[part 1 of 2: packages /AUTOSAR/V2xM/ClientServerInterfaces_Blueprint to /AUTOSAR/Csm/ClientServerInterfaces_Blueprint]
AUTOSAR XML (schema 00046)
package /AUTOSAR/V2xM/ClientServerInterfaces_Blueprint
  4 x client server interface, all with is-service=true:
    V2xM_GeoMath  # Interfaces for Applications to math functions
      operation Distance: possible-error=[V2xM_GeoMath/E_OK, V2xM_GeoMath/E_NOT_OK]  # Service for Calculating the distance between two geographical points
        5 x arg:
          latitudeA: type=sint32, direction=IN  # Latitude of geographical point A
          longitudeA: type=sint32, direction=IN  # Longitude of geographical point A
          latitudeB: type=sint32, direction=IN  # Latitude of geographical point B
          longitudeB: type=sint32, direction=IN  # Longitude of geographical point B
          distance: type=float32, direction=OUT  # Distance between geographical points A and B in [m].
      operation HeadingInTolerance: possible-error=[V2xM_GeoMath/E_OK, V2xM_GeoMath/E_NOT_OK]  # Service for Calculating if difference of heading values are within a tolerance value
        4 x arg:
          heading1: type=float32, direction=IN  # First heading value
          heading2: type=float32, direction=IN  # Next heading value
          toleranceValue: type=float32, direction=IN  # Tolerated difference between heading1 and heading2
          tolerated: type=boolean, direction=OUT  # Return value
      error E_OK: error-code=0  # Operation successful
      error E_NOT_OK: error-code=1  # Operation failed
    V2xM_PseudonymChange  # Interfaces for Applications to lock and unlock pseudonym changes within the V2X-BSW-Stack.
      operation Lock: possible-error=[V2xM_PseudonymChange/E_OK, V2xM_PseudonymChange/E_NOT_OK]  # Service for locking the pseudonym change. See [SWS_V2xM_00078] for more information about locking the pseudonym change.
        arg Duration: type=uint16, direction=IN  # Duration to lock.
        arg HandleId: type=uint64, direction=OUT  # HandleId for manual Unlock
      operation Unlock: possible-error=[V2xM_PseudonymChange/E_OK, V2xM_PseudonymChange/E_NOT_OK]  # Service for unlocking the pseudonym change. See [SWS_V2xM_00079] for more information about locking the pseudonym change.
        arg HandleId: type=uint64, direction=IN  # HandleId to unlock
      error E_OK: error-code=0  # Operation successful
      error E_NOT_OK: error-code=1  # Operation failed
    V2xM_Sec  # Security related interfaces for applications
      operation Verify: possible-error=[V2xM_Sec/E_OK, V2xM_Sec/E_NOT_OK]  # Interfaces for Applications to verify messages on demand instead of verify all incoming messages, to reduce ECU load.
        arg TransactionId32: type=uint32, direction=IN  # TransactionId of the packet to be verified
        arg SecReport: type=V2xM_SecReportType, direction=OUT
      error E_OK: error-code=0  # Operation successful
      error E_NOT_OK: error-code=1  # Operation failed
    V2xM_Vdp  # Interfaces for Vehicle Data Provider (VDP) to get and set V2X related vehicle information in the BSW V2X-Stack
      4 x operation, all with possible-error=[V2xM_Vdp/E_OK, V2xM_Vdp/E_NOT_OK]:
        GetNextLongTermCertificateExpirationDate  # Service to get the certificate expiration date of the long term certificates that expires in the nearest future.
          arg ExpirationDate: type=uint32, direction=OUT  # Date is based on format Time32 that is specified in [19].
        GetNextPseudonymCertificateExpirationDate  # Service to get the certificate expiration date of the pseudonym certificates that expires in the nearest future.
          arg ExpirationDate: type=uint32, direction=OUT  # Date is based on format Time32 that is specified in [19].
        GetTime32  # Service to get the current reference time.
          arg Time32: type=uint32, direction=OUT  # Time is based on TAI mod 2^32, where TAI is the number of elapsed TAI milliseconds since 2004-01-01 00:00:00.000.
        SetPositionAndTime  # Service for setting positional and time information relevant for the V2X-Stack
          arg positionAndTime: type=V2xM_PositionAndTimeType, direction=IN
      error E_OK: error-code=0  # Operation successful
      error E_NOT_OK: error-code=1  # Operation failed
package /AUTOSAR/V2xM/ServiceSwComponentTypes_Blueprint
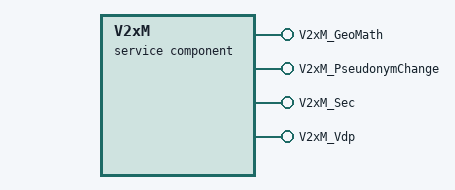
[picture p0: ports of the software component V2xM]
  service sw component type V2xM
    4 x provide port:
      V2xM_GeoMath: provided-interface=V2xM_GeoMath  # Service port for geographical calculation requests.
      V2xM_PseudonymChange: provided-interface=V2xM_PseudonymChange  # Service port for pseudonym lock and unlock requests.
      V2xM_Sec: provided-interface=V2xM_Sec  # Service port for security operations of V2X messages.
      V2xM_Vdp: provided-interface=V2xM_Vdp  # Service port for exchange of vehicle related data. This port is used by the Vehicle Data Provider SW-C.
    behavior V2xMInternalBehavior
package /AUTOSAR/V2xFac/ClientServerInterfaces_Blueprint
  client server interface V2xFacDenBs: is-service=true  # Service of V2xFac module basic service DEN
    operation TerminateEvent: possible-error=[V2xFacDenBs/E_OK, V2xFacDenBs/E_NOT_OK, E_ACTION_ID_NONEXISTENT, E_DENM_UNCONSTRUCTABLE, E_DENM_TIME_OUT]  # Requests termination of an existing DENM ( see [11] chapter 4 and 5.4.1.4 )
      6 x arg:
        EventData: type=V2xFac_DenMsgType, direction=IN  # Pre-filled DENM message structure, including the ActionID from TriggerEvent
        RepetitionDuration: type=uint32, direction=IN  # Duration of the DENM repetition in units of milliseconds
        RepetitionInterval: type=uint16, direction=IN  # Interval of DENM repetition in units of milliseconds
        DestinationArea: type=V2xFac_GnDestinationAreaType, direction=IN  # Destination area for DENM dissemination as specified in ETSI EN 302 931.
        TrafficClass: type=V2xFac_TrafficClassIdType, direction=IN  # GN traffic class of the DENM as defined in ETSI EN 302 636-4-1
        ActionID: type=V2xFac_ActionIdType, direction=OUT  # The DEN basic service returns the actionID or other applicable identifier created by the DEN basic service to the requesting ITS-S application
    operation TriggerEvent: possible-error=[V2xFacDenBs/E_OK, V2xFacDenBs/E_NOT_OK, E_DENM_UNCONSTRUCTABLE, E_DENM_TIME_OUT]  # Requests creation of a new DENM ( see [11] chapter 4 and 5.4.1.2 )
      6 x arg:
        EventData: type=V2xFac_DenMsgType, direction=IN  # Pre-filled DENM message structure
        RepetitionDuration: type=uint32, direction=IN  # Duration of the DENM repetition in units of milliseconds
        RepetitionInterval: type=uint16, direction=IN  # Interval of DENM repetition in units of milliseconds
        DestinationArea: type=V2xFac_GnDestinationAreaType, direction=IN  # Destination area for DENM dissemination as specified in ETSI EN 302 931.
        TrafficClass: type=V2xFac_TrafficClassIdType, direction=IN  # GN traffic class of the DENM as defined in ETSI EN 302 636-4-1
        ActionID: type=V2xFac_ActionIdType, direction=OUT  # The DEN basic service returns the actionID or other applicable identifier created by the DEN basic service to the requesting ITS-S application
    operation UpdateEvent: possible-error=[V2xFacDenBs/E_OK, V2xFacDenBs/E_NOT_OK, E_ACTION_ID_NONEXISTENT, E_DENM_UNCONSTRUCTABLE, E_DENM_TIME_OUT]  # Requests update of an existing DENM ( see [11] chapter 4 and 5.4.1.3 )
      6 x arg:
        EventData: type=V2xFac_DenMsgType, direction=IN  # Pre-filled DENM message structure, including the ActionID from TriggerEvent
        RepetitionDuration: type=uint32, direction=IN  # Duration of the DENM repetition in units of milliseconds
        RepetitionInterval: type=uint16, direction=IN  # Interval of DENM repetition in units of milliseconds
        DestinationArea: type=V2xFac_GnDestinationAreaType, direction=IN  # Destination area for DENM dissemination as specified in ETSI EN 302 931.
        TrafficClass: type=V2xFac_TrafficClassIdType, direction=IN  # GN traffic class of the DENM as defined in ETSI EN 302 636-4-1
        ActionID: type=V2xFac_ActionIdType, direction=OUT  # The DEN basic service returns the actionID or other applicable identifier created by the DEN basic service to the requesting ITS-S application
    5 x error:
      E_OK: error-code=0  # Operation successful
      E_NOT_OK: error-code=1  # Operation failed
      E_ACTION_ID_NONEXISTENT: error-code=2  # ActionID provided for Update/Termination does not exist
      E_DENM_UNCONSTRUCTABLE: error-code=3  # DENM couldn't be constructed
      E_DENM_TIME_OUT: error-code=4  # DENM hasn't been sent before timeout of DENM has been reached
package /AUTOSAR/V2xFac/SenderReceiverInterfaces_Blueprint
  6 x sender receiver interface:
    V2xApplRxIndicationCam: is-service=true  # Deliver received CAMs Applications
      data CamData: implementation-data-type=V2xFac_CamMessageRootType
    V2xApplRxIndicationDenm: is-service=true  # Deliver received DENMs to Applications
      data DenmData: implementation-data-type=V2xFac_DenmMessageRootType
    V2xApplRxIndicationIvim: is-service=true  # Deliver received IVIMs to Applications
      data IvimData: implementation-data-type=V2xFac_IvimDataType
    V2xApplRxIndicationMapem: is-service=true  # Deliver received MAPEMs to Applications
      data MapemData: implementation-data-type=V2xFac_MapemDataType
    V2xApplRxIndicationSpatem: is-service=true  # Deliver received SPATEMs to Applications
      data SpatemData: implementation-data-type=V2xFac_SpatemDataType
    V2xFacVdp  # Interface to receive data from VDP application
      data vdpData: implementation-data-type=V2xFac_CoopAwarenessType
package /AUTOSAR/V2xFac/ServiceSwComponentTypes_Blueprint
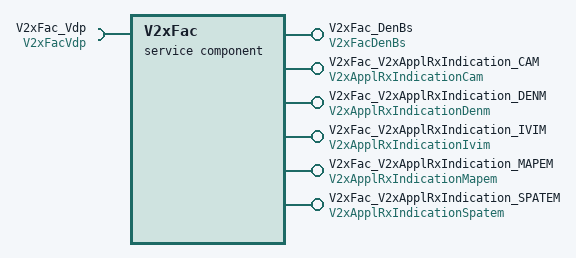
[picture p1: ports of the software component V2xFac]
  service sw component type V2xFac
    6 x provide port:
      V2xFac_DenBs: provided-interface=V2xFacDenBs  # Service port for DEN specific service requests
      V2xFac_V2xApplRxIndication_CAM: provided-interface=V2xApplRxIndicationCam  # Port for delivering received CAMs to application layer
      V2xFac_V2xApplRxIndication_DENM: provided-interface=V2xApplRxIndicationDenm  # Port for delivering received DENMs to application layer
      V2xFac_V2xApplRxIndication_IVIM: provided-interface=V2xApplRxIndicationIvim  # Port for delivering received IVIMs to application layer
      V2xFac_V2xApplRxIndication_MAPEM: provided-interface=V2xApplRxIndicationMapem  # Port for delivering received MAPEMs to application layer
      V2xFac_V2xApplRxIndication_SPATEM: provided-interface=V2xApplRxIndicationSpatem  # Port for delivering received SPATEMs to application layer
    require port V2xFac_Vdp: required-interface=V2xFacVdp  # Port for retrieving data from VDP application
    behavior V2xFacInternalBehavior
package /AUTOSAR/Dem/ClientServerInterfaces_Blueprint
  37 x client server interface, all with is-service=true:
    CallbackClearEventAllowed  # If configured, it gets the permission to clear a specific event from the SW-C. For each event, there can be one port of this interface type.
      operation ClearEventAllowed: possible-error=[CallbackClearEventAllowed/E_OK, CallbackClearEventAllowed/E_NOT_OK]
        arg Allowed: type=boolean, direction=OUT  # True - clearance of event is allowed False - clearance of event is not allowed
      error E_OK: error-code=0  # Operation successful
      error E_NOT_OK: error-code=1  # Operation failed
    CallbackEventDataChanged  # If configured it triggers SW-Cs on event related data changes. For each event, there can be one port of this interface type.
      operation EventDataChanged
    CallbackEventUdsStatusChanged  # If configured it triggers SW-Cs on event status byte changes. For each event, there can be several ports of this interface type.
      operation CallbackEventUdsStatusChanged
        arg EventStatusByteOld: type=Dem_UdsStatusByteType, direction=IN
        arg EventStatusByteNew: type=Dem_UdsStatusByteType, direction=IN
    CallbackGetFaultDetectCounter  # If configured it get the monitor-internal fault detection counter value of a specific event from the SW-C.
      operation GetFaultDetectionCounter: possible-error=[CallbackGetFaultDetectCounter/E_OK, CallbackGetFaultDetectCounter/E_NOT_OK]
        arg FaultDetectionCounter: type=sint8, direction=OUT  # Value of FaultDetectionCounter
      error E_OK: error-code=0  # Operation successful
      error E_NOT_OK: error-code=1  # Operation failed
    CallbackInitMonitorForEvent  # If configure it triggers an event-specific initialization of the monitor part of the SW-C). For each event, there can be one port of this interface type.
      operation InitMonitorForEvent: possible-error=[CallbackInitMonitorForEvent/E_OK, CallbackInitMonitorForEvent/E_NOT_OK]
        arg InitMonitorReason: type=Dem_InitMonitorReasonType, direction=IN
      error E_OK: error-code=0  # Operation successful
      error E_NOT_OK: error-code=1  # Operation failed
    CallbackMonitorStatusChange  # If configured it triggers SW-Cs on monitor status changes. For each event, there can be several ports of this interface type.
      operation MonitorStatusChanged
    CallbackComponentStatusChanged
      operation ComponentStatusChanged
        arg ComponentFailedStatus: type=boolean, direction=IN
    CallbackDTCStatusChange  # If configured it triggers SW-Cs on DTC status byte changes via DemCallbackDTCStatusChanged, DemCallbackOBDDTCStatusChanged, and / or DemCallbackJ1939DTCStatusChanged. There can be several ports of this interface type, provided globally by the Dem Service Component.
      operation DTCStatusChanged: possible-error=[CallbackDTCStatusChange/E_OK, CallbackDTCStatusChange/E_NOT_OK]
        arg DTC: type=uint32, direction=IN
        arg DTCStatusOld: type=Dem_UdsStatusByteType, direction=IN
        arg DTCStatusNew: type=Dem_UdsStatusByteType, direction=IN
      error E_OK: error-code=0  # Operation successful
      error E_NOT_OK: error-code=1  # Operation failed
    ClearDTC  # Provides the operations only related to complex device drivers. One port of this interface type is provided globally by the Dem Service Component. It has ClientId as a port-defined argument.
      operation ClearDTC: possible-error=[ClearDTC/E_OK, ClearDTC/E_NOT_OK, ClearDTC/DEM_PENDING, DEM_CLEAR_BUSY, DEM_CLEAR_MEMORY_ERROR, DEM_CLEAR_FAILED, ClearDTC/DEM_WRONG_DTC, ClearDTC/DEM_WRONG_DTCORIGIN, DEM_BUSY]
      operation SelectDTC: possible-error=[ClearDTC/E_OK, ClearDTC/E_NOT_OK]
        arg DTC: type=uint32, direction=IN
        arg DTCFormat: type=Dem_DTCFormatType, direction=IN
        arg DTCOrigin: type=Dem_DTCOriginType, direction=IN
      9 x error:
        E_OK: error-code=0  # Operation successful
        E_NOT_OK: error-code=1  # Operation failed
        DEM_PENDING: error-code=4  # Clearing the DTCs is currently in progress. The caller shall call this function again at a later moment.
        DEM_CLEAR_BUSY: error-code=5  # Another client is currently clearing DTCs. The requested operation will not be started and the caller shall try again at a later moment.
        DEM_CLEAR_MEMORY_ERROR: error-code=6  # An error occurred during erasing a memory location (e.g. if DemClearDTCBehavior is set to DEM_CLRRESP_NON-VOLATILE_FINISH and erasing of non-volatile-block failed).
        DEM_CLEAR_FAILED: error-code=7  # DTC clearing failed
        DEM_WRONG_DTC: error-code=8  # Selected DTC value in selected format does not exist or clearing is restricted by configuration to group of all DTCs only.
        DEM_WRONG_DTCORIGIN: error-code=9  # Selected DTCOrigin does not exist.
        DEM_BUSY: error-code=22  # A different Dem_SelectDTC dependent operation according to SWS_Dem_01253 of this client is currently in progress.
    ClearDtcNotification: variation-point={short-label=ClearDtcNotification, blueprint-condition=p=l-1=(count({ecuc(Dem/DemGeneral/DemEventMemorySet/DemClearDTCNotification/DemClearDtcNotificationFnc)} == NULL) > 0)}
      operation ClearDtcNotification: possible-error=ClearDtcNotification/E_OK
        arg DTC: type=uint32, direction=IN
        arg DTCFormat: type=Dem_DTCFormatType, direction=IN
        arg DTCOrigin: type=Dem_DTCOriginType, direction=IN
      error E_OK: error-code=0  # Operation successful
    DTCSuppression: variation-point={short-label=DTCSuppression, blueprint-condition=p=l-1=({ecuc(Dem/DemGeneral/DemSuppressionSupport)} == DEM_DTC_SUPPRESSION)}  # Provides the capability to control the suppression of DTCs. One port of this interface type is provided globally by the Dem Service Component.
      operation GetDTCSuppression: possible-error=[DTCSuppression/E_OK, DTCSuppression/E_NOT_OK, DTCSuppression/DEM_PENDING, DTCSuppression/DEM_WRONG_DTC, DTCSuppression/DEM_WRONG_DTCORIGIN]
        arg ClientID: type=uint8, direction=IN  # Unique client id, assigned to the instance of the calling module.
        arg SuppressionStatus: type=boolean, direction=OUT  # Defines whether the respective DTC is suppressed (TRUE) or enabled (FALSE).
      operation SetDTCSuppression: possible-error=[DTCSuppression/E_OK, DTCSuppression/E_NOT_OK, DTCSuppression/DEM_WRONG_DTC, DTCSuppression/DEM_WRONG_DTCORIGIN]
        arg ClientID: type=uint8, direction=IN  # Unique client id, assigned to the instance of the calling module.
        arg SuppressionStatus: type=boolean, direction=IN
      5 x error:
        E_OK: error-code=0  # Operation successful
        E_NOT_OK: error-code=1  # Operation failed
        DEM_PENDING: error-code=4  # Clearing the DTCs is currently in progress. The caller shall call this function again at a later moment.
        DEM_WRONG_DTC: error-code=8  # Selected DTC value in selected format does not exist or clearing is restricted by configuration to group of all DTCs only.
        DEM_WRONG_DTCORIGIN: error-code=9  # Selected DTCOrigin does not exist.
    EventAvailable: variation-point={short-label=EventAvailable, blueprint-condition=p=l-1={ecuc(Dem/DemGeneral/DemAvailabilitySupport)} == DEM_EVENT_AVAILABILITY}
      operation SetEventAvailable: possible-error=[EventAvailable/E_OK, EventAvailable/E_NOT_OK]
        arg AvailableStatus: type=boolean, direction=IN
      error E_OK: error-code=0  # Operation successful
      error E_NOT_OK: error-code=1  # Operation failed
    EventFailureCycleCounterThreshold: variation-point={short-label=EventFailureCycleCounterThreshold, blueprint-condition=p=l-1=(count({ecuc(Dem/DemConfigSet/DemEventParameter/DemEventFailureCycleCounterThresholdAdaptable)} == TRUE) > 0 )}  # Provides the capability for dynamical adaptation of the failure cycle threshold. One port of this interface is provided per diagnostic event with EventId as a port-defined argument.
      operation SetEventFailureCycleCounterThreshold: possible-error=[EventFailureCycleCounterThreshold/E_OK, EventFailureCycleCounterThreshold/E_NOT_OK]
        arg FailureCycleCounterThreshold: type=uint8, direction=IN  # Failure cycle counter threshold of event to be set.
      error E_OK: error-code=0  # Operation successful
      error E_NOT_OK: error-code=1  # Operation failed
    DataServices: variation-point={short-label=DataServicesCS, blueprint-condition=p=l-1=(({ecuc(Dem/DemGeneral/DemDataElementClass)} instanceof {ecuc(Dem/DemGeneral/DemDataElementClass/DemExternalCSDataElementClass)})&& ({ecuc(Dem/DemGeneral/DemDataElementClass/DemExternalCSDataElementClass/DemDataElementUsePort)} == true))}  # If configured it gets the data element value contained in a DID, a PID, or an extended data record from the respective SW-C via client/server or sender/receiver communication (refer to Figure "Dem and Dcm module requests PID data elements of SW-C via ReadData operation"). For each data element, one port of this interface type is provided by the SW-Cs.
      operation ReadData: possible-error=[DataServices/E_OK, DataServices/E_NOT_OK]  # The server is not allowed to return E_NOT_OK, but shall always provide a valid data value (e.g. a default/replacement value in an error-case) to Dcm/Dem nevertheless the signature of the operation includes E_NOT_OK to ensure compatibility between server runnable and RTE Call API, since the RTE may return negative Std_Return values in certain cases (e.g. partition of server stopped)
        arg Data: type=Dem_DataType, direction=OUT
        arg monitorData0: type=Dem_MonitorDataType, direction=IN, variation-point=blueprint-condition=p=l-1=({ecuc(Dem/DemGeneral/DemDataElementClass/DemExternalCSDataElementClass/DemDataElementProvideMonitorData)} == true))
      error E_OK: error-code=0  # Operation successful
      error E_NOT_OK: error-code=1  # Operation failed
    DiagnosticMonitor_MonitorData  # Provide means to report diagnostic monitor status with monitor data.
      operation SetEventStatusWithMonitorData: possible-error=[DiagnosticMonitor_MonitorData/E_OK, DiagnosticMonitor_MonitorData/E_NOT_OK]
        arg EventStatus: type=Dem_EventStatusType, direction=IN
        arg monitorData0: type=Dem_MonitorDataType, direction=IN
        arg monitorData1: type=Dem_MonitorDataType, direction=IN
      error E_OK: error-code=0  # Operation successful
      error E_NOT_OK: error-code=1  # Operation failed
    DTRCentralReport  # Available if OBD support is configured.
      operation SetDTR: possible-error=[DTRCentralReport/E_OK, DTRCentralReport/E_NOT_OK]
        4 x arg, all with direction=IN:
          TestResult: type=sint32
          LowerLimit: type=sint32
          UpperLimit: type=sint32
          Ctrlval: type=Dem_DTRControlType
      error E_OK: error-code=0  # Operation successful
      error E_NOT_OK: error-code=1  # Operation failed
    EnableCondition  # If at least one enable condition is configured it provide the capability to set an enable condition. One port of this interface type is provided per enable condition by the Dem Service Component. It has EnableConditionId as a port-defined argument.
      operation SetEnableCondition: possible-error=[EnableCondition/E_OK, EnableCondition/E_NOT_OK]
        arg ConditionFulfilled: type=boolean, direction=IN
      error E_OK: error-code=0  # Operation successful
      error E_NOT_OK: error-code=1  # Operation failed
    DiagnosticMonitor  # Provide the capability to modify the event information. One port of this interface type is provided per application-related diagnostic event by the Dem Service Component. It has EventId as a port-defined argument.
      6 x operation, all with possible-error=[DiagnosticMonitor/E_OK, DiagnosticMonitor/E_NOT_OK]:
        ClearPrestoredFreezeFrame: variation-point=blueprint-condition=p=l-1={ecuc(Dem/DemGeneral/DemMaxNumberPrestoredFF)} > 0
        PrestoreFreezeFrame: variation-point=blueprint-condition=p=l-1={ecuc(Dem/DemGeneral/DemMaxNumberPrestoredFF)} > 0
        ResetEventDebounceStatus: variation-point=blueprint-condition=p=l-1=({ecuc(Dem/DemGeneral/DemDebounceCounterBasedSupport)} == true) || ({ecuc(Dem/DemGeneral/DemDebounceTimeBasedSupport)} == true)
          arg DebounceResetStatus: type=Dem_DebounceResetStatusType, direction=IN
        ResetEventStatus
        SetEventDisabled: variation-point=blueprint-condition=p=l-1={ecuc(Dem/DemGeneral.DemOBDSupport)} != DEM_OBD_NO_OBD_SUPPORT
        SetEventStatus
          arg EventStatus: type=Dem_EventStatusType, direction=IN
      error E_OK: error-code=0  # Operation successful
      error E_NOT_OK: error-code=1  # Operation failed
    DiagnosticInfo  # Provides the capability to obtain the event information. One port of this interface type is provided per diagnostic event by the Dem Service Component. It has EventId as a port-defined argument.
      7 x operation:
        GetDTCOfEvent: possible-error=[DiagnosticInfo/E_OK, DiagnosticInfo/E_NOT_OK, DiagnosticInfo/DEM_E_NO_DTC_AVAILABLE]
          arg DTCFormat: type=Dem_DTCFormatType, direction=IN
          arg DTCOfEvent: type=uint32, direction=OUT
        GetDebouncingOfEvent: possible-error=[DiagnosticInfo/E_OK, DiagnosticInfo/E_NOT_OK], variation-point=blueprint-condition=p=l-1=(({ecuc(Dem/DemConfigSet/DemEventParameter/DemDebounceAlgorithmClass)} instanceof {ecuc(Dem/DemConfigSet/DemEventParameter/DemDebounceAlgorithmClass/DemDebounceCounterBased)}) ||({ecuc(Dem/DemConfigSet/DemEventParameter/DemDebounceAlgorithmClass)} instanceof {ecuc(Dem/DemConfigSet/DemEventParameter/DemDebounceAlgorithmClass/DemDebounceTimeBase)}))
          arg DebouncingState: type=Dem_DebouncingStateType, direction=OUT  # Bit 0 Temporarily Defective (corresponds to 0 < FDC < 127) Bit 1 finally Defective (corresponds to FDC = 127) Bit 2 temporarily healed (corresponds to -128 < FDC < 0) Bit 3 Test complete (corresponds to FDC = -128 or FDC = 127) Bit 4 DTR Update (= Test complete && Debouncing complete && enable conditions / storage conditions fulfilled)
        GetEventExtendedDataRecordEx: possible-error=[DiagnosticInfo/E_OK, DiagnosticInfo/E_NOT_OK, DiagnosticInfo/DEM_BUFFER_TOO_SMALL, DiagnosticInfo/DEM_NO_SUCH_ELEMENT]
          arg RecordNumber: type=uint8, direction=IN
          arg DestBuffer: type=Dem_MaxDataValueType, direction=OUT
          arg Bufsize: type=uint16, direction=INOUT
        GetEventFreezeFrameDataEx: possible-error=[DiagnosticInfo/E_OK, DiagnosticInfo/E_NOT_OK, DiagnosticInfo/DEM_BUFFER_TOO_SMALL, DiagnosticInfo/DEM_NO_SUCH_ELEMENT]
          4 x arg:
            RecordNumber: type=uint8, direction=IN
            DataId: type=uint16, direction=IN
            DestBuffer: type=Dem_MaxDataValueType, direction=OUT
            BufSize: type=uint16, direction=INOUT
        GetEventUdsStatus: possible-error=[DiagnosticInfo/E_OK, DiagnosticInfo/E_NOT_OK]  # Gets the current UDS status byte assigned to the DTC for the event
          arg UDSStatusByte: type=Dem_UdsStatusByteType, direction=OUT
        GetFaultDetectionCounter: possible-error=[DiagnosticInfo/E_OK, DiagnosticInfo/E_NOT_OK, DiagnosticInfo/DEM_E_NO_FDC_AVAILABLE]
          arg FaultDetectionCounter: type=sint8, direction=OUT
        GetMonitorStatus: possible-error=[DiagnosticInfo/E_OK, DiagnosticInfo/E_NOT_OK]
          arg MonitorStatus: type=Dem_MonitorStatusType, direction=OUT  # Monitor status byte of the requested event. If the return value of the function call is E_NOT_OK, this parameter does not contain valid data.
      6 x error:
        E_OK: error-code=0  # Operation successful
        E_NOT_OK: error-code=1  # Operation failed
        DEM_E_NO_DTC_AVAILABLE: error-code=10  # there is no DTC configured in the requested format
        DEM_E_NO_FDC_AVAILABLE: error-code=14  # there is no fault detection counter available for the requested event
        DEM_BUFFER_TOO_SMALL: error-code=21  # The provided buffer size is too small
        DEM_NO_SUCH_ELEMENT: error-code=48  # The requested event data is not currently stored (but the request was valid) OR The requested record number is not supported by the event OR The requested DID is not supported by the freeze frame (GetEventFreezeFrameDataEx)
    EventStatus  # Provides the capability modify the event status. One port of this interface type is provided per application-related diagnostic event by the Dem Service Component. It has EventId as a port-defined argument.
      operation SetWIRStatus: possible-error=[EventStatus/E_OK, EventStatus/E_NOT_OK]
        arg WIRStatus: type=boolean, direction=IN
      error E_OK: error-code=0  # Operation successful
      error E_NOT_OK: error-code=1  # Operation failed
    GeneralCallbackEventDataChanged
      operation EventDataChanged
        arg EventId: type=Dem_EventIdType, direction=IN
    GeneralCallbackMonitorStatusChanged
      operation MonitorStatusChanged
        arg EventId: type=Dem_EventIdType, direction=IN
    GeneralCallbackEventUdsStatusChanged
      operation GeneralCallbackEventUdsStatusChanged
        arg EventId: type=Dem_EventIdType, direction=IN
        arg EventStatusByteOld: type=Dem_UdsStatusByteType, direction=IN
        arg EventStatusByteNew: type=Dem_UdsStatusByteType, direction=IN
    GeneralDiagnosticInfo
      7 x operation:
        GetDTCOfEvent: possible-error=[GeneralDiagnosticInfo/E_OK, GeneralDiagnosticInfo/E_NOT_OK, GeneralDiagnosticInfo/DEM_E_NO_DTC_AVAILABLE]
          arg EventId: type=Dem_EventIdType, direction=IN
          arg DTCFormat: type=Dem_DTCFormatType, direction=IN
          arg DTCOfEvent: type=uint32, direction=OUT
        GetDebouncingOfEvent: possible-error=[GeneralDiagnosticInfo/E_OK, GeneralDiagnosticInfo/E_NOT_OK], variation-point=blueprint-condition=p=l-1=(({ecuc(Dem/DemConfigSet/DemEventParameter/DemDebounceAlgorithmClass)} instanceof {ecuc(Dem/DemConfigSet/DemEventParameter/DemDebounceAlgorithmClass/DemDebounceCounterBased)}) ||({ecuc(Dem/DemConfigSet/DemEventParameter/DemDebounceAlgorithmClass)} instanceof {ecuc(Dem/DemConfigSet/DemEventParameter/DemDebounceAlgorithmClass/DemDebounceTimeBase)}))
          arg EventId: type=Dem_EventIdType, direction=IN
          arg DebouncingState: type=Dem_DebouncingStateType, direction=OUT  # Bit 0 Temporarily Defective (corresponds to 0 < FDC < 127) Bit 1 finally Defective (corresponds to FDC = 127) Bit 2 temporarily healed (corresponds to -128 < FDC < 0) Bit 3 Test complete (corresponds to FDC = -128 or FDC = 127) Bit 4 DTR Update (= Test complete && Debouncing complete && enable conditions / storage conditions fulfilled)
        GetEventExtendedDataRecordEx: possible-error=[GeneralDiagnosticInfo/E_OK, GeneralDiagnosticInfo/E_NOT_OK, GeneralDiagnosticInfo/DEM_BUFFER_TOO_SMALL, GeneralDiagnosticInfo/DEM_NO_SUCH_ELEMENT]
          4 x arg:
            EventId: type=Dem_EventIdType, direction=IN
            RecordNumber: type=uint8, direction=IN
            DestBuffer: type=Dem_MaxDataValueType, direction=OUT
            Bufsize: type=uint16, direction=INOUT
        GetEventFreezeFrameDataEx: possible-error=[GeneralDiagnosticInfo/E_OK, GeneralDiagnosticInfo/E_NOT_OK, GeneralDiagnosticInfo/DEM_BUFFER_TOO_SMALL, GeneralDiagnosticInfo/DEM_NO_SUCH_ELEMENT]
          5 x arg:
            EventId: type=Dem_EventIdType, direction=IN
            RecordNumber: type=uint8, direction=IN
            DataId: type=uint16, direction=IN
            DestBuffer: type=Dem_MaxDataValueType, direction=OUT
            BufSize: type=uint16, direction=INOUT
        GetEventUdsStatus: possible-error=[GeneralDiagnosticInfo/E_OK, GeneralDiagnosticInfo/E_NOT_OK]  # Gets the current UDS status byte assigned to the DTC for the event
          arg EventId: type=Dem_EventIdType, direction=IN
          arg UDSStatusByte: type=Dem_UdsStatusByteType, direction=OUT
        GetFaultDetectionCounter: possible-error=[GeneralDiagnosticInfo/E_OK, GeneralDiagnosticInfo/E_NOT_OK, GeneralDiagnosticInfo/DEM_E_NO_FDC_AVAILABLE]
          arg EventId: type=Dem_EventIdType, direction=IN
          arg FaultDetectionCounter: type=sint8, direction=OUT
        GetMonitorStatus: possible-error=[GeneralDiagnosticInfo/E_OK, GeneralDiagnosticInfo/E_NOT_OK]
          arg EventID: type=Dem_EventIdType, direction=IN  # Identification of an event by assigned EventId.
          arg MonitorStatus: type=Dem_MonitorStatusType, direction=OUT  # Monitor status byte of the requested event. If the return value of the function call is E_NOT_OK, this parameter does not contain valid data.
      6 x error:
        E_OK: error-code=0  # Operation successful
        E_NOT_OK: error-code=1  # Operation failed
        DEM_E_NO_DTC_AVAILABLE: error-code=10  # there is no DTC configured in the requested format
        DEM_E_NO_FDC_AVAILABLE: error-code=14  # there is no fault detection counter available for the requested event
        DEM_BUFFER_TOO_SMALL: error-code=21  # The provided buffer size is too small
        DEM_NO_SUCH_ELEMENT: error-code=48  # The requested event data is not currently stored (but the request was valid) OR The requested record number is not supported by the event OR The requested DID is not supported by the freeze frame (GetEventFreezeFrameDataEx)
    GetDataOfPID21
      operation GetDataOfPID21: possible-error=[GetDataOfPID21/E_OK, GetDataOfPID21/E_NOT_OK]
        arg PID21value: type=Dem_PID21valueType, direction=OUT
      error E_OK: error-code=0  # Operation successful
      error E_NOT_OK: error-code=1  # Operation failed
    IndicatorStatus  # One port of this interface type is provided per indicator by the Dem Service Component. It has IndicatorId as a port-defined argument.
      operation GetIndicatorStatus: possible-error=[IndicatorStatus/E_OK, IndicatorStatus/E_NOT_OK]
        arg IndicatorStatus: type=Dem_IndicatorStatusType, direction=OUT
      error E_OK: error-code=0  # Operation successful
      error E_NOT_OK: error-code=1  # Operation failed
    IUMPRDenominator  # If OBD is configured it provides the capability to define the number of times the vehicle operation has been fulfilled. One port of this interface type is provided per ratio Id by the Dem Service Component. It has RatioID as a port-defined argument.
      operation RepIUMPRDenRelease: possible-error=[IUMPRDenominator/E_OK, IUMPRDenominator/E_NOT_OK]
      error E_OK: error-code=0  # Operation successful
      error E_NOT_OK: error-code=1  # Operation failed
    IUMPRDenominatorCondition  # If OBD is configured it broadcasts the status information of the General Denominator and additional denominator conditions among all OBD relevant ECUs. One port of this interface type is provided per denominator condition Id by the Dem Service Component. It has Dem_IumprDenomCondId as a port-defined argument.
      operation GetIUMPRDenCondition: possible-error=[IUMPRDenominatorCondition/E_OK, IUMPRDenominatorCondition/E_NOT_OK]
        arg ConditionStatus: type=Dem_IumprDenomCondStatusType, direction=OUT
      operation SetIUMPRDenCondition: possible-error=[IUMPRDenominatorCondition/E_OK, IUMPRDenominatorCondition/E_NOT_OK]
        arg ConditionStatus: type=Dem_IumprDenomCondStatusType, direction=IN
      error E_OK: error-code=0  # Operation successful
      error E_NOT_OK: error-code=1  # Operation failed
    IUMPRNumerator  # If OBD is configured it provides the capability to define the number of times a fault could have been found. One port of this interface type is provided per ratio Id by the Dem Service Component. It has RatioID as a port-defined argument.
      operation RepIUMPRFaultDetect: possible-error=[IUMPRNumerator/E_OK, IUMPRNumerator/E_NOT_OK]
      error E_OK: error-code=0  # Operation successful
      error E_NOT_OK: error-code=1  # Operation failed
    OperationCycle  # Provides the capability to set the state of an operation cycle. One port of this interface type is provided per operation cycle by the Dem Service Component. It has OperationCycleId as a port-defined argument.
      operation GetCycleQualified: possible-error=[OperationCycle/E_OK, OperationCycle/E_NOT_OK]
        arg isQualified: type=boolean, direction=OUT
      operation RestartOperationCycle: possible-error=[OperationCycle/E_OK, OperationCycle/E_NOT_OK]
      operation SetCycleQualified: possible-error=[OperationCycle/E_OK, OperationCycle/E_NOT_OK]
      error E_OK: error-code=0  # Operation successful
      error E_NOT_OK: error-code=1  # Operation failed
    EvMemOverflowIndication  # If the respective event memory is configured it provides the status of the event memory). One port of this interface type is provided per supported event memory by the Dem Service Component. It has DTCOrigin as a port-defined argument.
      operation GetEventMemoryOverflow: possible-error=[EvMemOverflowIndication/E_OK, EvMemOverflowIndication/E_NOT_OK]
        arg OverflowIndication: type=boolean, direction=OUT
      operation GetNumberOfEventMemoryEntries: possible-error=[EvMemOverflowIndication/E_OK, EvMemOverflowIndication/E_NOT_OK]
        arg GetNumberOfEventMemoryEntries: type=uint8, direction=OUT
      error E_OK: error-code=0  # Operation successful
      error E_NOT_OK: error-code=1  # Operation failed
    PowerTakeOff  # Available if OBD support is configured. One port of this interface type is provided by the Dem Service Component.
      operation SetPtoStatus: possible-error=[PowerTakeOff/E_OK, PowerTakeOff/E_NOT_OK]
        arg PtoStatus: type=boolean, direction=IN
      error E_OK: error-code=0  # Operation successful
      error E_NOT_OK: error-code=1  # Operation failed
    SetDataOfPID21
      operation SetDataOfPID21: possible-error=[SetDataOfPID21/E_OK, SetDataOfPID21/E_NOT_OK]
        arg PID21value: type=Dem_PID21valueType, direction=IN
      error E_OK: error-code=0  # Operation successful
      error E_NOT_OK: error-code=1  # Operation failed
    SetDataOfPID31
      operation SetDataOfPID31: possible-error=[SetDataOfPID31/E_OK, SetDataOfPID31/E_NOT_OK]
        arg PID31value: type=Dem_PID31valueType, direction=IN
      error E_OK: error-code=0  # Operation successful
      error E_NOT_OK: error-code=1  # Operation failed
    SetDataOfPID4D
      operation SetDataOfPID4D: possible-error=SetDataOfPID4D/E_OK
        arg PID4Dvalue: type=Dem_PID4DvalueType, direction=IN
      error E_OK: error-code=0  # Operation successful
    SetDataOfPID4E
      operation SetDataOfPID4E: possible-error=SetDataOfPID4E/E_OK
        arg PID4Evalue: type=Dem_PID4EvalueType, direction=IN
      error E_OK: error-code=0  # Operation successful
    StorageCondition  # Provides the capability to set a storage condition if at least one storage condition is configured. One port of this interface type is provided per storage condition by the Dem Service Component. It has StorageConditionId as a port-defined argument.
      operation SetStorageCondition: possible-error=[StorageCondition/E_OK, StorageCondition/E_NOT_OK]
        arg ConditionFulfilled: type=boolean, direction=IN  # This parameter specifies whether the enable condition assigned to the EnableConditionID is fulfilled (TRUE) or not fulfilled (FALSE).
      error E_OK: error-code=0  # Operation successful
      error E_NOT_OK: error-code=1  # Operation failed
package /AUTOSAR/Dem/SenderReceiverInterfaces_Blueprint
  sender receiver interface DataServices: variation-point={short-label=DataServicesSR, blueprint-condition=p=l-1=({ecuc(Dem/DemGeneral/DemDataElementClass)} instanceof {ecuc(Dem/DemGeneral/DemDataElementClass/DemExternalSRDataElementClass)})}
    data data: implementation-data-type=Dem_DataType
package /AUTOSAR/Dem/ServiceSwComponentTypes_Blueprint
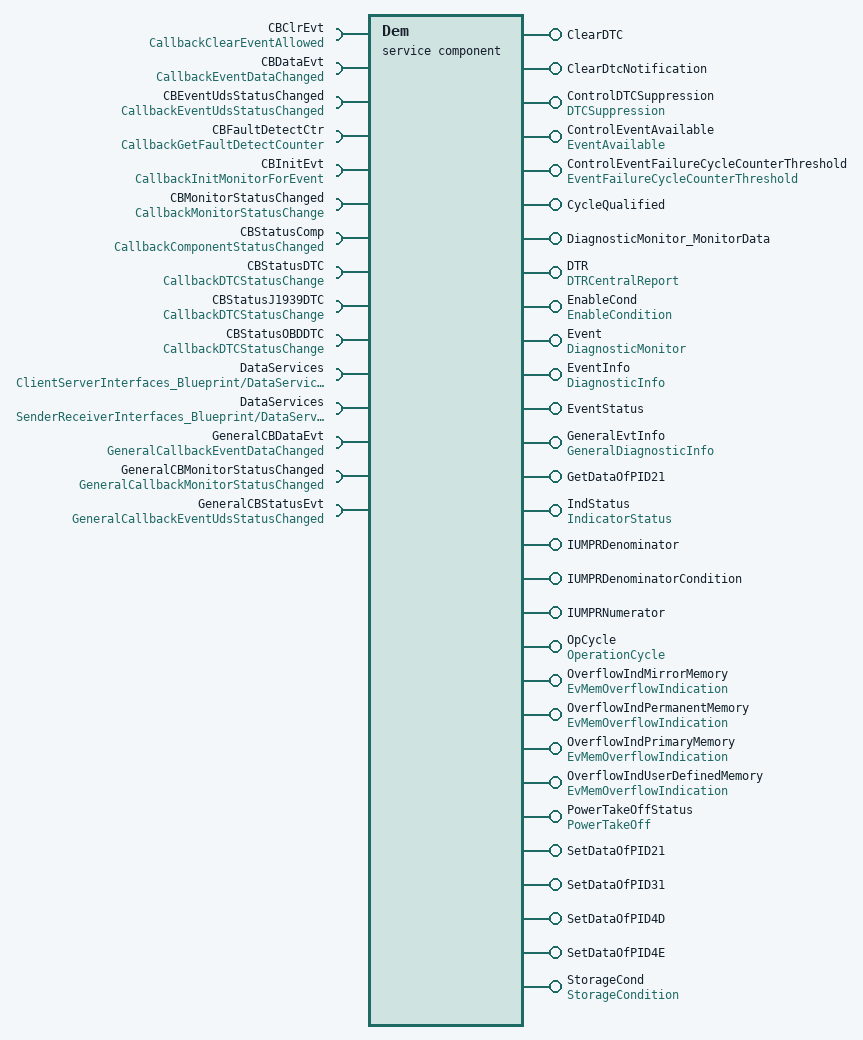
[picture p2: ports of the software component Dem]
  service sw component type Dem
    10 x require port:
      CBClrEvt: variation-point=blueprint-condition=p=l-1=(({ecuc(Dem/DemConfigSet/DemEventParameter/DemCallbackClearEventAllowed)} != NULL) &&({ecuc(Dem/DemConfigSet/DemEventParameter/DemCallbackClearEventAllowed/DemCallbackClearEventAllowedFnc)} == NULL)), required-interface=CallbackClearEventAllowed
      CBDataEvt: variation-point=blueprint-condition=p=l-1=(({ecuc(Dem/DemConfigSet/DemEventParameter/DemCallbackEventDataChanged)} != NULL) &&({ecuc(Dem/DemConfigSet/DemEventParameter/DemCallbackEventDataChanged/DemCallbackEventDataChangedFnc)} == NULL)), required-interface=CallbackEventDataChanged
      CBEventUdsStatusChanged: required-interface=CallbackEventUdsStatusChanged
      CBFaultDetectCtr: variation-point=blueprint-condition=p=l-1=({ecuc(Dem/DemConfigSet/DemEventParameter/DemDebounceAlgorithmClass/DemDebounceMonitorInternal/DemCallbackGetFDC/DemCallbackGetFDCFnc)} == NULL), required-interface=CallbackGetFaultDetectCounter
      CBInitEvt: variation-point=blueprint-condition=p=l-1=(({ecuc(Dem/DemConfigSet/DemEventParameter/DemCallbackInitMForE)} != NULL) &&({ecuc(Dem/DemConfigSet/DemEventParameter/DemCallbackInitMForE/DemCallbackInitMForEFnc)} == NULL)), required-interface=CallbackInitMonitorForEvent
      CBMonitorStatusChanged: variation-point=blueprint-condition=p=l-1=({ecuc(Dem/DemConfigSet/DemEventParameter.DemEventKind)} == DEM_EVENT_KIND_SWC), required-interface=CallbackMonitorStatusChange
      CBStatusComp: variation-point=blueprint-condition=p=l-1=({ecuc(Dem/DemConfigSet/DemComponent.DemComponentFailedCallbackUsePort )}== TRUE), required-interface=CallbackComponentStatusChanged
      CBStatusDTC: required-interface=CallbackDTCStatusChange
      CBStatusJ1939DTC: required-interface=CallbackDTCStatusChange
      CBStatusOBDDTC: required-interface=CallbackDTCStatusChange
    6 x provide port:
      ClearDTC: variation-point=blueprint-condition=p=l-1=({ecuc(Dem/DemGeneral/DemClient/DemClientUsesRte)}==True) && ({ecuc(Dem/DemGeneral/DemClient/DemClientFunctionality)} == DEM_CLIENT_USES_FULL_FUNCTIONALITY), provided-interface=ClearDTC
      ClearDtcNotification: variation-point=blueprint-condition=p=l-1=({ecuc(Dem/DemGeneral/DemEventMemorySet/DemClearDTCNotification/DemClearDtcNotificationFnc)}== NULL), provided-interface=ClearDtcNotification  # called by the Dem when performing a clear DTC operation
      ControlDTCSuppression: variation-point=blueprint-condition=p=l-1=({ecuc(Dem/DemGeneral/DemSuppressionSupport)} == DEM_DTC_SUPPRESSION), provided-interface=DTCSuppression
      ControlEventAvailable: variation-point=blueprint-condition=p=l-1={ecuc(Dem/DemGeneral/DemAvailabilitySupport)} == DEM_EVENT_AVAILABILITY, provided-interface=EventAvailable
      ControlEventFailureCycleCounterThreshold: variation-point=blueprint-condition=p=l-1={ecuc(Dem/DemConfigSet/DemEventParameter/DemEventFailureCycleCounterThresholdAdaptable)} == TRUE, provided-interface=EventFailureCycleCounterThreshold
      CycleQualified: variation-point=blueprint-condition=p=l-1=({ecuc(Dem/DemGeneral.DemOBDSupport)} != DEM_OBD_NO_OBD_SUPPORT) &&({ecuc(Dem/DemGeneral/DemEventMemorySet/DemMaxNumberEventEntryPermanent)} > 0)
    require port DataServices: variation-point={short-label=DataServices_DataServicesCS, blueprint-condition=[l-1=(({ecuc(Dem/DemGeneral/DemDataElementClass)} instanceof {ecuc(Dem/DemGeneral/DemDataElementClass/DemExternalCSDataElementClass)})&& ({ecuc(Dem/DemGeneral/DemDataElementClass/DemExternalCSDataElementClass/DemDataElementUsePort)} == TRUE))|| ({ecuc(Dem/DemGeneral/DemDataElementClass)} instanceof {ecuc(Dem/DemGeneral/DemDataElementClass/DemExternalSRDataElementClass)}), l-1=(({ecuc(Dem/DemGeneral/DemDataElementClass)} instanceof {ecuc(Dem/DemGeneral/DemDataElementClass/DemExternalCSDataElementClass)})&& ({ecuc(Dem/DemGeneral/DemDataElementClass/DemExternalCSDataElementClass/DemDataElementUsePort)} == true))]}, required-interface=ClientServerInterfaces_Blueprint/DataServices
    require port DataServices: variation-point={short-label=DataServices_DataServicesSR, blueprint-condition=[l-1=(({ecuc(Dem/DemGeneral/DemDataElementClass)} instanceof {ecuc(Dem/DemGeneral/DemDataElementClass/DemExternalCSDataElementClass)})&& ({ecuc(Dem/DemGeneral/DemDataElementClass/DemExternalCSDataElementClass/DemDataElementUsePort)} == TRUE))|| ({ecuc(Dem/DemGeneral/DemDataElementClass)} instanceof {ecuc(Dem/DemGeneral/DemDataElementClass/DemExternalSRDataElementClass)}), l-1=({ecuc(Dem/DemGeneral/DemDataElementClass)} instanceof {ecuc(Dem/DemGeneral/DemDataElementClass/DemExternalSRDataElementClass)})]}, required-interface=SenderReceiverInterfaces_Blueprint/DataServices
    6 x provide port:
      DiagnosticMonitor_MonitorData: provided-interface=DiagnosticMonitor_MonitorData
      DTR: variation-point=blueprint-condition=p=l-1=({ecuc(Dem/DemGeneral.DemOBDSupport)} != DEM_OBD_NO_OBD_SUPPORT), provided-interface=DTRCentralReport
      EnableCond: provided-interface=EnableCondition
      Event: provided-interface=DiagnosticMonitor
      EventInfo: provided-interface=DiagnosticInfo
      EventStatus: provided-interface=EventStatus
    require port GeneralCBDataEvt: variation-point=blueprint-condition=p=l-1=({ecuc(Dem/DemGeneral/DemGeneralInterfaceSupport)} == True), required-interface=GeneralCallbackEventDataChanged
    require port GeneralCBMonitorStatusChanged: variation-point=blueprint-condition=p=l-1=({ecuc(Dem/DemGeneral/DemGeneralInterfaceSupport)} == True), required-interface=GeneralCallbackMonitorStatusChanged
    require port GeneralCBStatusEvt: variation-point=blueprint-condition=p=l-1=({ecuc(Dem/DemGeneral/DemGeneralInterfaceSupport)} == True), required-interface=GeneralCallbackEventUdsStatusChanged
    17 x provide port:
      GeneralEvtInfo: variation-point=blueprint-condition=p=l-1=({ecuc(Dem/DemGeneral/DemGeneralInterfaceSupport)} == True), provided-interface=GeneralDiagnosticInfo
      GetDataOfPID21: variation-point=blueprint-condition=p=l-1=({ecuc(Dem/DemGeneral/DemGeneralOBD.DemOBDCentralizedPID21Handling)} == true) && ({ecuc(Dem/DemGeneral.DemOBDSupport)} == DEM_OBD_MASTER_ECU), provided-interface=GetDataOfPID21
      IndStatus: provided-interface=IndicatorStatus
      IUMPRDenominator: variation-point=blueprint-condition=p=l-1=({ecuc(Dem/DemGeneral.DemOBDSupport)} != DEM_OBD_NO_OBD_SUPPORT), provided-interface=IUMPRDenominator
      IUMPRDenominatorCondition: variation-point=blueprint-condition=p=l-1=({ecuc(Dem/DemGeneral.DemOBDSupport)} != DEM_OBD_NO_OBD_SUPPORT), provided-interface=IUMPRDenominatorCondition
      IUMPRNumerator: variation-point=blueprint-condition=p=l-1=({ecuc(Dem/DemGeneral.DemOBDSupport)} != DEM_OBD_NO_OBD_SUPPORT), provided-interface=IUMPRNumerator
      OpCycle: provided-interface=OperationCycle
      OverflowIndMirrorMemory: variation-point=blueprint-condition=p=l-1=({ecuc(Dem/DemGeneral/DemEventMemorySet/DemMirrorMemory)} != NULL) &&(({ecuc(Dem/DemGeneral/DemClient/DemClientUsesRte )} ==TRUE)), provided-interface=EvMemOverflowIndication
      OverflowIndPermanentMemory: variation-point=blueprint-condition=p=l-1=({ecuc(Dem/DemGeneral/DemEventMemorySet/DemMaxNumberEventEntryPermanent)} > 0), provided-interface=EvMemOverflowIndication
      OverflowIndPrimaryMemory: variation-point=blueprint-condition=p=l-1=(({ecuc(Dem/DemGeneral/DemClient/DemClientUsesRte)} ==TRUE)), provided-interface=EvMemOverflowIndication
      OverflowIndUserDefinedMemory: variation-point=blueprint-condition=p=l-1=({ecuc(Dem/DemGeneral/DemClient/DemEventMemorySetRef->DemEventMemorySet/DemUserDefinedMemory != NULL)})(({ecuc(Dem/DemGeneral/DemClient/DemClientUsesRte)} ==TRUE)), provided-interface=EvMemOverflowIndication
      PowerTakeOffStatus: variation-point=blueprint-condition=p=l-1={ecuc(Dem/DemGeneral.DemOBDSupport)} != DEM_OBD_NO_OBD_SUPPORT, provided-interface=PowerTakeOff
      SetDataOfPID21: variation-point=blueprint-condition=p=l-1=({ecuc(Dem/DemGeneral/DemGeneralOBD.DemOBDCentralizedPID21Handling)} == true) && ({ecuc(Dem/DemGeneral.DemOBDSupport)} == DEM_OBD_PRIMARY_ECU), provided-interface=SetDataOfPID21
      SetDataOfPID31: variation-point=blueprint-condition=p=l-1=({ecuc(Dem/DemGeneral.DemOBDSupport)} != DEM_OBD_NO_OBD_SUPPORT) && ({ecuc(Dem/DemGeneral/DemGeneralOBD.DemOBDCentralizedPID31Handling)} == true), provided-interface=SetDataOfPID31
      SetDataOfPID4D: variation-point=blueprint-condition=p=l-1=({ecuc(Dem/DemGeneral.DemOBDSupport)} == DEM_OBD_MASTER_ECU), provided-interface=SetDataOfPID4D
      SetDataOfPID4E: variation-point=blueprint-condition=p=l-1=({ecuc(Dem/DemGeneral.DemOBDSupport)} == DEM_OBD_MASTER_ECU), provided-interface=SetDataOfPID4E
      StorageCond: provided-interface=StorageCondition
    behavior DemInternalBehavior
      port-api-options:
        {port-defined-argument-value{value=undefined, value-type=uint8}, port=ClearDTC}
        {port-defined-argument-value{value=undefined, value-type=Dem_EventIdType}, port=ControlEventAvailable}
        {port-defined-argument-value{value=undefined, value-type=Dem_EventIdType}, port=ControlEventFailureCycleCounterThreshold}
        {port-defined-argument-value{value=undefined, value-type=Dem_EventIdType}, port=DiagnosticMonitor_MonitorData}
        {port-defined-argument-value{value=undefined, value-type=uint16}, port=DTR}
        {port-defined-argument-value{value=undefined, value-type=uint8}, port=EnableCond}
        {port-defined-argument-value{value=undefined, value-type=Dem_EventIdType}, port=Event}
        {port-defined-argument-value{value=undefined, value-type=Dem_EventIdType}, port=EventInfo}
        {port-defined-argument-value{value=undefined, value-type=Dem_EventIdType}, port=EventStatus}
        {port-defined-argument-value{value=undefined, value-type=uint8}, port=IndStatus}
        {port-defined-argument-value{value=undefined, value-type=Dem_RatioIdType}, port=IUMPRDenominator}
        {port-defined-argument-value{value=undefined, value-type=Dem_IumprDenomCondIdType}, port=IUMPRDenominatorCondition}
        {port-defined-argument-value{value=undefined, value-type=Dem_RatioIdType}, port=IUMPRNumerator}
        {port-defined-argument-value{value=undefined, value-type=uint8}, port=OpCycle}
        {port-arg-values=[{value=undefined, value-type=uint8}, {value=undefined, value-type=Dem_DTCOriginType}], port=OverflowIndMirrorMemory}
        {port-defined-argument-value{value=undefined, value-type=Dem_DTCOriginType}, port=OverflowIndPermanentMemory}
        {port-arg-values=[{value=undefined, value-type=uint8}, {value=undefined, value-type=Dem_DTCOriginType}], port=OverflowIndPrimaryMemory}
        {port-arg-values=[{value=undefined, value-type=uint8}, {value=undefined, value-type=Dem_DTCOriginType}], port=OverflowIndUserDefinedMemory}
        {port-defined-argument-value{value=undefined, value-type=uint8}, port=StorageCond}
package /AUTOSAR/Det/ClientServerInterfaces_Blueprint
  client server interface DETService: is-service=true  # Service of Default Error Tracer
    operation ReportError: possible-error=DETService/E_OK  # calls Det_ReportError with the Module ID of the port
      arg ApiId: type=uint8, direction=IN  # ID of API service in which error is detected (defined in SWS of calling module).
      arg ErrorId: type=uint8, direction=IN  # ID of detected development error (defined in SWS of calling module).
    operation ReportRuntimeError: possible-error=DETService/E_OK  # calls ReportRuntimeError with the Module ID of the port
      arg ApiId: type=uint8, direction=IN  # ID of API service in which error is detected (defined in SWS of calling module).
      arg ErrorId: type=uint8, direction=IN  # ID of detected runtime error (defined in SWS of calling module).
    error E_OK: error-code=0  # Operation successful
package /AUTOSAR/Det/ServiceSwComponentTypes_Blueprint
  service sw component type Det
    provide port Det: provided-interface=DETService
    behavior DetInternalBehavior: port-api-option{port-arg-values=[{value=undefined, value-type=uint16}, {value=undefined, value-type=uint8}], port=Det}
package /AUTOSAR/Dlt/ClientServerInterfaces_Blueprint
  4 x client server interface, all with is-service=true:
    DltControlService
      15 x operation:
        GetDefaultLogLevel: possible-error=[DltControlService/E_OK, DltControlService/DLT_E_ERROR]
          arg defaultLoglevel: type=Dlt_MessageLogLevelType, direction=OUT
        GetDefaultTraceStatus: possible-error=[DltControlService/E_OK, DltControlService/DLT_E_ERROR]
          arg logChannelName: type=Dlt_LogChannelNameType, direction=IN
          arg traceStatus: type=boolean, direction=OUT
        GetLogChannelNames: possible-error=[DltControlService/E_OK, DltControlService/DLT_E_ERROR]
          arg numberOfLogChannels: type=uint8, direction=INOUT
          arg logChannelNames: category=DATA_REFERENCE, sw-pointer-target-props={target-category=VALUE, implementation-data-type=Dlt_LogChannelNameType}, direction=OUT
        GetLogChannelThreshold: possible-error=[DltControlService/E_OK, DltControlService/DLT_E_ERROR]
          arg logChannelName: type=Dlt_LogChannelNameType, direction=IN
          arg logChannelThreshold: type=Dlt_MessageLogLevelType, direction=IN
          arg traceStatusPtr: type=boolean, direction=OUT
        GetLogInfo: possible-error=[DltControlService/E_OK, DltControlService/DLT_E_ERROR]
          5 x arg:
            options: type=uint8, direction=IN
            appId: type=Dlt_ApplicationIDType, direction=IN
            contextId: type=Dlt_ContextIDType, direction=IN
            status: type=uint8, direction=OUT
            logInfo: type=Dlt_LogInfoType, direction=OUT
        GetTraceStatus: possible-error=[DltControlService/E_OK, DltControlService/DLT_E_ERROR]
          arg appId: type=Dlt_ApplicationIDType, direction=IN
          arg contextId: type=Dlt_ContextIDType, direction=IN
          arg traceStatus: type=boolean, direction=OUT
        ResetToFactoryDefault: possible-error=[DltControlService/E_OK, DltControlService/DLT_E_ERROR]
        SetDefaultLogLevel: possible-error=[DltControlService/E_OK, DltControlService/DLT_E_ERROR]
          arg newDefaultLogLevel: type=Dlt_MessageLogLevelType, direction=IN
        SetDefaultTraceStatus: possible-error=[DltControlService/E_OK, DltControlService/DLT_E_ERROR]
          arg newTraceStatus: type=boolean, direction=IN
          arg logChannel: type=uint8, direction=IN
        SetLogChannelAssignment: possible-error=[DltControlService/E_OK, DltControlService/DLT_E_ERROR]
          4 x arg, all with direction=IN:
            appId: type=Dlt_ApplicationIDType
            contextId: type=Dlt_ContextIDType
            logChannelName: type=Dlt_LogChannelNameType
            addRemoveOp: type=Dlt_AssignmentOperation
        SetLogChannelThreshold: possible-error=[DltControlService/E_OK, DltControlService/DLT_E_ERROR]
          arg logChannelName: type=Dlt_LogChannelNameType, direction=IN
          arg newLogLevelThreshold: type=Dlt_MessageLogLevelType, direction=IN
          arg newTraceStatus: type=boolean, direction=IN
        SetLogLevel: possible-error=[DltControlService/E_OK, DltControlService/DLT_E_ERROR]
          arg appId: type=Dlt_ApplicationIDType, direction=IN
          arg contextId: type=Dlt_ContextIDType, direction=IN
          arg newLogLevel: type=Dlt_MessageLogLevelType, direction=IN
        SetMessageFiltering: possible-error=[DltControlService/E_OK, DltControlService/DLT_E_ERROR]
          arg status: type=boolean, direction=IN
        SetTraceStatus: possible-error=[DltControlService/E_OK, DltControlService/DLT_E_ERROR]
          arg appId: type=Dlt_ApplicationIDType, direction=IN
          arg contextId: type=Dlt_ContextIDType, direction=IN
          arg newTraceStatus: type=boolean, direction=IN
        StoreConfiguration: possible-error=[DltControlService/E_OK, DLT_E_NOT_SUPPORTED, DltControlService/DLT_E_ERROR]
      error E_OK: error-code=0  # Operation successful
      error DLT_E_NOT_SUPPORTED: error-code=7  # Service is not supported
      error DLT_E_ERROR: error-code=9
    InjectionCallback
      operation InjectCall: possible-error=[InjectionCallback/E_OK, InjectionCallback/E_NOT_OK]
        5 x arg, all with direction=IN:
          appId: type=Dlt_ApplicationIDType
          contextId: type=Dlt_ContextIDType
          serviceId: type=uint32
          dataLength: type=uint32
          data: category=DATA_REFERENCE, type=Dlt_uint8Ptr
      error E_OK: error-code=0  # Operation successful
      error E_NOT_OK: error-code=1  # Operation failed
    LogTraceSessionControl
      operation LogLevelChangedNotification: possible-error=LogTraceSessionControl/E_OK
        arg appId: type=Dlt_ApplicationIDType, direction=IN
        arg contextId: type=Dlt_ContextIDType, direction=IN
        arg logLevel: type=Dlt_MessageLogLevelType, direction=IN
      operation TraceStatusChangedNotification: possible-error=LogTraceSessionControl/E_OK
        arg appId: type=Dlt_ApplicationIDType, direction=IN
        arg contextId: type=Dlt_ContextIDType, direction=IN
        arg newTraceStatus: type=boolean, direction=IN
      error E_OK: error-code=0  # Operation successful
      error E_NOT_OK: error-code=1  # Operation failed
    DltSwcMessageService
      4 x operation:
        RegisterContext: possible-error=[DltSwcMessageService/E_OK, DLT_E_CONTEXT_ALREADY_REG, DLT_E_UNKNOWN_SESSION_ID]
          6 x arg, all with direction=IN:
            appId: type=Dlt_ApplicationIDType
            contextId: type=Dlt_ContextIDType
            appDescription: type=uint8
            lenAppDescription: type=uint8
            contextDescription: type=uint8
            lenContextDescription: type=uint8
        SendLogMessage: possible-error=[DltSwcMessageService/E_OK, DLT_E_MSG_TOO_LARGE, DLT_E_UNKNOWN_SESSION_ID, DLT_E_NO_BUFFER]
          arg logInfo: type=Dlt_MessageLogInfoType, direction=IN
          arg logData: type=uint8, direction=IN
          arg logDataLength: type=uint16, direction=IN
        SendTraceMessage: possible-error=[DltSwcMessageService/E_OK, DLT_E_MSG_TOO_LARGE, DLT_E_UNKNOWN_SESSION_ID, DLT_E_NO_BUFFER]
          arg traceInfo: type=Dlt_MessageTraceInfoType, direction=IN
          arg traceData: type=uint8, direction=IN
          arg traceDataLength: type=uint16, direction=IN
        UnregisterContext: possible-error=[DltSwcMessageService/E_OK, DLT_E_UNKNOWN_SESSION_ID, DLT_E_CONTEXT_NOT_YET_REG]
          arg appId: type=Dlt_ApplicationIDType, direction=IN
          arg contextId: type=Dlt_ContextIDType, direction=IN
      7 x error:
        E_OK: error-code=0  # Operation successful
        DLT_E_MSG_TOO_LARGE: error-code=2  # The message is too big for the internal Dlt buffer.
        DLT_E_CONTEXT_ALREADY_REG: error-code=3  # The software module context has already registered.
        DLT_E_UNKNOWN_SESSION_ID: error-code=4  # The provided session id is unknown.
        DLT_E_NO_BUFFER: error-code=5  # Buffer overflow.
        DLT_E_CONTEXT_NOT_YET_REG: error-code=6  # The software module context has not registered before.
        DLT_E_ERROR: error-code=9
package /AUTOSAR/Dlt/ServiceSwComponentTypes_Blueprint
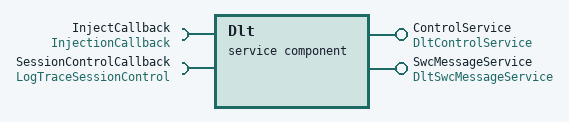
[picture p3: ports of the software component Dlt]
  service sw component type Dlt
    provide port ControlService: provided-interface=DltControlService  # Through this port SW-Cs can control log settings and other configurationitems of DLT.
    require port InjectCallback: required-interface=InjectionCallback  # Callback Port to registered Application, which processes Injection.
    require port SessionControlCallback: required-interface=LogTraceSessionControl  # Port used by Dlt to notify registered SW-C about LogLevel/TraceLevel Changes.
    provide port SwcMessageService: provided-interface=DltSwcMessageService  # Through this port SW-Cs can register/unregister their contexts and send out log and trace messages.
    behavior DltInternalBehavior: port-api-option{port-defined-argument-value{value=undefined, value-type=Dlt_SessionIDType}, port=SwcMessageService}
package /AUTOSAR/FiM/ClientServerInterfaces_Blueprint
  client server interface ControlFunctionAvailable: variation-point={short-label=ControlFunctionAvailable, blueprint-condition=p=l-1=({ecuc(FiM/FiMGeneral/FiMAvailabilitySupport)} == True)}, is-service=true  # SW Components can use this service to set the availability of a function.
    operation SetFunctionAvailable: possible-error=[ControlFunctionAvailable/E_OK, ControlFunctionAvailable/E_NOT_OK]  # Sets the availability of a function.
      arg Availability: type=boolean, direction=IN  # The permission of the requested FID: TRUE: Function is available. FALSE: Function is not available.
    error E_OK: error-code=0  # Operation successful
    error E_NOT_OK: error-code=1  # Operation failed
  client server interface FunctionInhibition: is-service=true  # The SW Components can use this service to query for the permission to execute a certain functionality represented by a FID.
    operation GetFunctionPermission: possible-error=[FunctionInhibition/E_OK, FunctionInhibition/E_NOT_OK]  # Get the permission state of the respective FID.
      arg Permission: type=boolean, direction=OUT  # The permission of the requested FID. TRUE: FID has permission to run FALSE: FID has no permission to run, i.e. shall not be executed
    error E_OK: error-code=0  # Operation successful
    error E_NOT_OK: error-code=1  # Operation failed
package /AUTOSAR/FiM/ServiceSwComponentTypes_Blueprint
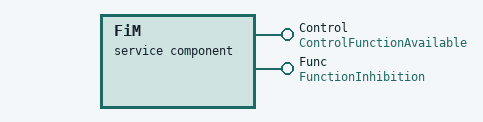
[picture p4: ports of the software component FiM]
  service sw component type FiM
    provide port Control: variation-point=blueprint-condition=p=l-1=({ecuc(FiM/FiMGeneral/FiMAvailabilitySupport)} == True), provided-interface=ControlFunctionAvailable  # A client can set the availability for a specific function.
    provide port Func: provided-interface=FunctionInhibition  # A client can query the FiM for execution permission for a specific function. The FIDs which represent the functions are not directly used by the client SW-C. Instead, the mechanism of "port-defined argument values" is used and every FID is mapped to a separate port that is responsible for the data exchange via RTE.
    behavior FiMInternalBehavior
      port-api-options:
        {port-defined-argument-value{value=undefined, value-type=FiM_FunctionIdType}, port=Control}
        {port-defined-argument-value{value=undefined, value-type=FiM_FunctionIdType}, port=Func}
package /AUTOSAR/ComM/ClientServerInterfaces_Blueprint
  4 x client server interface, all with is-service=true:
    ComM_ChannelLimitation: variation-point={short-label=ComM_ChannelLimitation, blueprint-condition=p=l-1={ecuc(ComM/ComMGeneral.ComMModeLimitationEnabled)} == true}  # A SW-C playing the role of a "Mode Manager" can use this interface to configure the Communication Manager Module to inhibit communication mode for a given channel.
      operation GetInhibitionStatus: possible-error=[ComM_ChannelLimitation/E_OK, ComM_ChannelLimitation/E_NOT_OK]  # returns the inhibition status of a channel
        arg Status: type=ComM_InhibitionStatusType, direction=OUT
      operation LimitChannelToNoComMode: possible-error=[ComM_ChannelLimitation/E_OK, ComM_ChannelLimitation/E_NOT_OK]  # Changes the inhibition status for the channel for changing from COMM_NO_COMMUNICATION to a higher Communication Mode. (See also ComM_LimitECUToNoComMode, same functionality but for all channels)
        arg Status: type=boolean, direction=IN  # FALSE: Limit channel to COMM_NO_COMMUNICATION disabled TRUE: Limit channel to COMM_NO_COMMUNICATION enabled
      error E_OK: error-code=0  # Operation successful
      error E_NOT_OK: error-code=1  # Operation failed
    ComM_ChannelWakeup: variation-point={short-label=ComM_ChannelWakeup, blueprint-condition=p=l-1={ecuc(ComM/ComMGeneral.ComMWakeupInhibitionEnabled)} == true}  # A SW-C playing the role of a "Mode Manager" can use this interface to configure the Communication Manager Module to take precautions against awakening other ECU's by starting the communication.
      operation GetInhibitionStatus: possible-error=[ComM_ChannelWakeup/E_OK, ComM_ChannelWakeup/E_NOT_OK]  # returns the inhibition status of a channel
        arg Status: type=ComM_InhibitionStatusType, direction=OUT
      operation PreventWakeUp: possible-error=[ComM_ChannelWakeup/E_OK, ComM_ChannelWakeup/E_NOT_OK]  # Changes the inhibition status COMM_NO_WAKEUP for the corresponding channel.
        arg Status: type=boolean, direction=IN
      error E_OK: error-code=0  # Operation successful
      error E_NOT_OK: error-code=1  # Operation failed
    ComM_ECUModeLimitation: variation-point={short-label=ComM_ECUModeLimitation, blueprint-condition=p=l-1={ecuc(ComM/ComMGeneral.ComMModeLimitationEnabled)} == true}  # A SW-C which plays the role of a "Mode Manager" can use this interface to change the behavior of the entire ECU.
      4 x operation, all with possible-error=[ComM_ECUModeLimitation/E_OK, ComM_ECUModeLimitation/E_NOT_OK]:
        LimitECUToNoComMode  # Changes the inhibition status for the ECU (=all channels) for changing from COMM_NO_COMMUNICATION to a higher Communication Mode. (See also ComM_LimitChannelToNoComMode, same functionality but for a specific channels)
          arg Status: type=boolean, direction=IN  # FALSE: Limit ECU to COMM_NO_COMMUNICATION disabled TRUE: Limit ECU to COMM_NO_COMMUNICATION enabled
        ReadInhibitCounter: variation-point=blueprint-condition=p=l-1={ecuc(ComM/ComMGeneral.ComMGlobalNvMBlockDescriptor)} != NULL  # returns the value of the 'inhibited full communication request counter'
          arg CounterValue: type=uint16, direction=OUT
        ResetInhibitCounter: variation-point=blueprint-condition=p=l-1={ecuc(ComM/ComMGeneral.ComMGlobalNvMBlockDescriptor)} != NULL  # reset the "inhibited full communication request counter"
        SetECUGroupClassification  # changes the ECU group classification status
          arg Status: type=ComM_InhibitionStatusType, direction=IN
      error E_OK: error-code=0  # Operation successful
      error E_NOT_OK: error-code=1  # Operation failed
    ComM_UserRequest  # A SW-C that wants to explicitly direct the local Communication Manager Module of the ECU towards a certain state requires the client-server interface ComM_UserRequest. Through this interface the SW-C can set the desired state of all communication channels that are relevant for that component to "No Communication" or "Full Communication".
      4 x operation:
        GetCurrentComMode: possible-error=[ComM_UserRequest/E_OK, ComM_UserRequest/E_NOT_OK]  # Returns the current Communication Manager Module mode for the SW-C
          arg ComMode: type=ComM_ModeType, direction=OUT
        GetMaxComMode: possible-error=[ComM_UserRequest/E_OK, ComM_UserRequest/E_NOT_OK]  # Returns the current Communication Manager Module mode for the SW-C
          arg ComMode: type=ComM_ModeType, direction=OUT
        GetRequestedComMode: possible-error=[ComM_UserRequest/E_OK, ComM_UserRequest/E_NOT_OK]  # Returns that last Communication Manager Module Mode requested by the SW-C
          arg ComMode: type=ComM_ModeType, direction=OUT
        RequestComMode: possible-error=[ComM_UserRequest/E_OK, ComM_UserRequest/E_NOT_OK, E_MODE_LIMITATION]  # The SW-C requests that all communication channels it needs are in the provided Communication Manager Module mode
          arg ComMode: type=ComM_ModeType, direction=IN
      error E_OK: error-code=0  # Operation successful
      error E_NOT_OK: error-code=1  # Operation failed
      error E_MODE_LIMITATION: error-code=2  # ComMMode cannot be granted because of ComMMode inhibition
package /AUTOSAR/ComM/SenderReceiverInterfaces_Blueprint
  sender receiver interface ComM_CurrentChannelRequest: variation-point={short-label=ComM_CurrentChannelRequest, blueprint-condition=p=l-1={ecuc(ComM/ComMConfigSet/ComMChannel/ComMFullCommRequestNotificationEnabled)} == true}, is-service=true  # Array of ComMUserIdentifier, that currently hold FULL_COM requests for this channel. The size of the attribute fullComRequestors.handleArray is NUM_COMM_USER_PER_CHANNEL
    data fullComRequestors: implementation-data-type=ComM_UserHandleArrayType, variation-point=blueprint-condition=p=l-1=channel_name = {ecuc(ComM/ComMConfigSet/ComMChannel.SHORT-NAME)}
package /AUTOSAR/ComM/ServiceSwComponentTypes_Blueprint
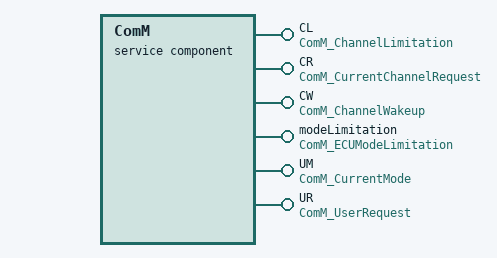
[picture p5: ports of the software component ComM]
  service sw component type ComM
    6 x provide port:
      CL: variation-point=blueprint-condition=p=l-1={ecuc(ComM/ComMGeneral.ComMModeLimitationEnabled)} == true, provided-interface=ComM_ChannelLimitation
      CR: variation-point=blueprint-condition=p=l-1={ecuc(ComM/ComMConfigSet/ComMChannel/ComMFullCommRequestNotificationEnabled)} == true, provided-interface=ComM_CurrentChannelRequest
      CW: variation-point=blueprint-condition=p=l-1={ecuc(ComM/ComMGeneral.ComMWakeupInhibitionEnabled)} == true, provided-interface=ComM_ChannelWakeup
      modeLimitation: variation-point=blueprint-condition=p=l-1={ecuc(ComM/ComMGeneral.ComMModeLimitationEnabled)} == true, provided-interface=ComM_ECUModeLimitation
      UM: provided-interface=ComM_CurrentMode
      UR: provided-interface=ComM_UserRequest
    behavior ComMInternalBehavior
      port-api-options:
        {port-defined-argument-value{value=undefined, value-type=NetworkHandleType}, port=CL}
        {port-defined-argument-value{value=undefined, value-type=NetworkHandleType}, port=CW}
        {port-defined-argument-value{value=undefined, value-type=ComM_UserHandleType}, port=UR}
package /AUTOSAR/ComM/ModeDeclarationGroups_Blueprint
  mode declaration group ComMMode: category=ALPHABETIC_ORDER, initial-mode=COMM_NO_COMMUNICATION
    mode COMM_FULL_COMMUNICATION
    mode COMM_NO_COMMUNICATION
    mode COMM_SILENT_COMMUNICATION
package /AUTOSAR/ComM/ModeSwitchInterfaces_Blueprint
  mode switch interface ComM_CurrentMode: is-service=true  # A SW-C that wants to get informed about its current Communication Manager Module Mode requires the ModeSwitchInterface ComM_CurrentMode.
    mode group currentMode: type=ComMMode
package /AUTOSAR/EcuM_flex/ClientServerInterfaces_Blueprint
  5 x client server interface, all with is-service=true:
    EcuM_AlarmClock: variation-point={short-label=EcuM_AlarmClock, blueprint-condition=p=l-1={ecuc(EcuM/EcuMFlexGeneral/EcuMAlarmClockPresent)} == True}  # A SW-C that wants to use an alarm clock must use the client-server interface EcuM_AlarmClock.
      4 x operation:
        AbortWakeupAlarm: possible-error=[EcuM_AlarmClock/E_OK, EcuM_AlarmClock/E_NOT_OK, ECUM_E_NOT_ACTIVE]  # Aborts the wakeup alarm previously set by this user
        SetAbsWakeupAlarm: possible-error=[EcuM_AlarmClock/E_OK, EcuM_AlarmClock/E_NOT_OK, ECUM_E_EARLIER_ACTIVE, ECUM_E_PAST]  # Sets the user's wakeup alarm to an absolute point in time
          arg time: type=EcuM_TimeType, direction=IN  # Absolute time in seconds. Note that, absolute alarms use knowledge of the current time
        SetClock: possible-error=[EcuM_AlarmClock/E_OK, EcuM_AlarmClock/E_NOT_OK]  # Sets the EcuM clock time to the provided value
          arg time: type=EcuM_TimeType, direction=IN  # Absolute time in seconds since battery connect
        SetRelWakeupAlarm: possible-error=[EcuM_AlarmClock/E_OK, EcuM_AlarmClock/E_NOT_OK, ECUM_E_EARLIER_ACTIVE]  # Sets a user's wakeup alarm relative to the current point in time
          arg time: type=EcuM_TimeType, direction=IN  # Relative time from now in seconds
      5 x error:
        E_OK: error-code=0  # Operation successful
        E_NOT_OK: error-code=1  # Operation failed
        ECUM_E_EARLIER_ACTIVE: error-code=3  # An earlier alarm is already set
        ECUM_E_PAST: error-code=4  # The desired point in time has already passed
        ECUM_E_NOT_ACTIVE: error-code=5  # No active alarm found
    EcuM_BootTarget  # A SW-C that wants to select a boot target must use the client-server interface EcuM_BootTarget.
      operation GetBootTarget: possible-error=EcuM_BootTarget/E_OK  # Returns the current boot target
        arg target: type=EcuM_BootTargetType, direction=OUT  # The currently selected boot target
      operation SelectBootTarget: possible-error=[EcuM_BootTarget/E_OK, EcuM_BootTarget/E_NOT_OK]  # Selects a boot target
        arg target: type=EcuM_BootTargetType, direction=IN  # The selected boot target
      error E_OK: error-code=0  # Operation successful
      error E_NOT_OK: error-code=1  # Operation failed
    EcuM_ShutdownTarget  # A SW-C can select a shutdown target using this interface
      5 x operation, all with possible-error=[EcuM_ShutdownTarget/E_OK, EcuM_ShutdownTarget/E_NOT_OK]:
        GetLastShutdownTarget  # Returns the shutdown target of the previous shutdown
          arg shutdownTarget: type=EcuM_ShutdownTargetType, direction=OUT  # The shutdown target of the previous shutdown
          arg shutdownMode: type=EcuM_ShutdownModeType, direction=OUT  # The sleep mode (if target is ECUM_SHUTDOWN_TARGET_SLEEP) or the reset mechanism (if target is ECUM_SHUTDOWN_TARGET_RESET) of the shutdown
        GetShutdownCause  # Returns the selected shutdown cause as set by the operation SelectShutdownCause.
          arg shutdownCause: type=EcuM_ShutdownCauseType, direction=OUT  # The selected cause of the next shutdown
        GetShutdownTarget  # Returns the currently selected shutdown target for the next shutdown as set by the operation SelectShutdownTarget.
          arg shutdownTarget: type=EcuM_ShutdownTargetType, direction=OUT  # The shutdown target of the next shutdown
          arg shutdownMode: type=EcuM_ShutdownModeType, direction=OUT  # The sleep mode (if target is ECUM_SHUTDOWN_TARGET_SLEEP) or the reset mechanism (if target is ECUM_SHUTDOWN_TARGET_RESET) of the shutdown
        SelectShutdownCause
          arg shutdownCause: type=EcuM_ShutdownCauseType, direction=IN  # The selected shutdown cause
        SelectShutdownTarget  # The SW-C selects the cause corresponding to the next shutdown target
          arg shutdownTarget: type=EcuM_ShutdownTargetType, direction=IN  # The selected shutdown cause
          arg shutdownMode: type=EcuM_ShutdownModeType, direction=IN  # The identfier of a sleep mode (if shutdownTarget is ECUM_SHUTDOWN_TARGET_SLEEP) or a reset mechanism (if shutdownTarget is ECUM_SHUTDOWN_TARGET_RESET) as defined by configuration.
      error E_OK: error-code=0  # Operation successful
      error E_NOT_OK: error-code=1  # Operation failed
    EcuM_StateRequest  # Interface to request a specific ECU state
      4 x operation, all with possible-error=[EcuM_StateRequest/E_OK, EcuM_StateRequest/E_NOT_OK]:
        ReleasePOSTRUN
        ReleaseRUN
        RequestPOSTRUN
        RequestRUN
      error E_OK: error-code=0  # Operation successful
      error E_NOT_OK: error-code=1  # Operation failed
    EcuM_Time
      operation GetCurrentTime: possible-error=[EcuM_Time/E_OK, EcuM_Time/E_NOT_OK]  # Returns the current value of the EcuM clock (i.e. the time in seconds since battery connect)
        arg time: type=EcuM_TimeType, direction=OUT  # Absolute time in seconds since battery connect
      operation GetWakeupTime: possible-error=[EcuM_Time/E_OK, EcuM_Time/E_NOT_OK]  # Returns the current value of the master alarm clock (the minimum absolute time of all user alarm clocks)
        arg time: type=EcuM_TimeType, direction=OUT  # Absolute time in seconds for next wakeup. 0xFFFFFFFF means no active alarm.
      error E_OK: error-code=0  # Operation successful
      error E_NOT_OK: error-code=1  # Operation failed
package /AUTOSAR/EcuM_flex/ServiceSwComponentTypes_Blueprint
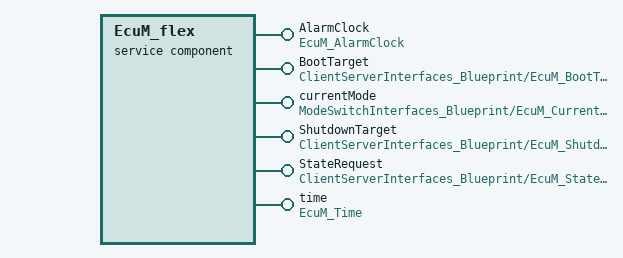
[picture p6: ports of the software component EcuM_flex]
  service sw component type EcuM_flex
    6 x provide port:
      AlarmClock: variation-point=blueprint-condition=p=l-1={ecuc(EcuM/EcuMFlexGeneral/EcuMAlarmClockPresent)} == true, provided-interface=EcuM_AlarmClock  # Provides to SW-Cs an alarm clock. The EcuM_AlarmClock port uses port-defined argument values to identify the user that manages its alarm clock.
      BootTarget: provided-interface=ClientServerInterfaces_Blueprint/EcuM_BootTarget  # Provides an interface to SW-Cs to select a new boot target and query the current boot target.
      currentMode: provided-interface=ModeSwitchInterfaces_Blueprint/EcuM_CurrentMode
      ShutdownTarget: provided-interface=ClientServerInterfaces_Blueprint/EcuM_ShutdownTarget  # Provides an interface to SW-Cs to select a new shutdown target and query the current shutdown target.
      StateRequest: provided-interface=ClientServerInterfaces_Blueprint/EcuM_StateRequest  # Provides an interface to SW-Cs to request state changes of the ECU state. The port uses port-defined argument values to identify the user.
      time: provided-interface=EcuM_Time  # Provides the EcuM's time service to SWCs
    behavior EcuM_flexInternalBehavior
      port-api-options:
        {port-defined-argument-value{value=undefined, value-type=EcuM_UserType}, port=AlarmClock}
        {port-defined-argument-value{value=undefined, value-type=EcuM_UserType}, port=EcuM_flex/StateRequest}
package /AUTOSAR/EcuM_flex/ModeDeclarationGroups_Blueprint
  mode declaration group EcuM_Mode: category=ALPHABETIC_ORDER, initial-mode=EcuM_Mode/STARTUP
    6 x mode:
      POST_RUN
      RUN
      SHUTDOWN
      SLEEP
      STARTUP
      WAKE_SLEEP
package /AUTOSAR/EcuM_flex/ModeSwitchInterfaces_Blueprint
  mode switch interface EcuM_CurrentMode: is-service=true  # Interface to read the current ECU mode
    mode group currentMode: type=ModeDeclarationGroups_Blueprint/EcuM_Mode
package /AUTOSAR/EcuM/ClientServerInterfaces_Blueprint
  client server interface EcuM_BootTarget: is-service=true  # Interfaces to manage the boot target
    operation GetBootTarget: possible-error=[EcuM_BootTarget/E_OK, EcuM_BootTarget/E_NOT_OK]  # Read the current boot target
      arg target: type=EcuM_BootTargetType, direction=OUT
    operation SelectBootTarget: possible-error=[EcuM_BootTarget/E_OK, EcuM_BootTarget/E_NOT_OK]  # Select a new boot target
      arg target: type=EcuM_BootTargetType, direction=IN
    error E_OK: error-code=0  # Operation successful
    error E_NOT_OK: error-code=1  # Operation failed
  client server interface EcuM_ShutdownTarget: is-service=true  # Interfaces to manage the shutdown target
    operation GetLastShutdownTarget: possible-error=[EcuM_ShutdownTarget/E_OK, EcuM_ShutdownTarget/E_NOT_OK]  # GetLastShutdownTarget returns the shutdown target of the previous shutdown process.
      arg shutdownTarget: type=EcuM_StateType, direction=OUT
      arg sleepMode: type=EcuM_SleepModeType, direction=OUT
    operation GetShutdownTarget: possible-error=[EcuM_ShutdownTarget/E_OK, EcuM_ShutdownTarget/E_NOT_OK]  # GetShutdownTarget returns the currently selected shutdown target as set by SelectShutdownTarget
      arg shutdownTarget: type=EcuM_StateType, direction=OUT
      arg sleepMode: type=EcuM_SleepModeType, direction=OUT
    operation SelectShutdownTarget: possible-error=[EcuM_ShutdownTarget/E_OK, EcuM_ShutdownTarget/E_NOT_OK]  # Select a new shutdown target
      arg shutdownTarget: type=EcuM_StateType, direction=IN
      arg sleepMode: type=EcuM_SleepModeType, direction=IN
    error E_OK: error-code=0  # Operation successful
    error E_NOT_OK: error-code=1  # Operation failed
  client server interface EcuM_StateRequest: is-service=true  # Interface to request a specific ECU state
    4 x operation, all with possible-error=[EcuM_StateRequest/E_OK, EcuM_StateRequest/E_NOT_OK]:
      ReleasePOSTRUN
      ReleaseRUN
      RequestPOSTRUN
      RequestRUN
    error E_OK: error-code=0  # Operation successful
    error E_NOT_OK: error-code=1  # Operation failed
package /AUTOSAR/EcuM/ServiceSwComponentTypes_Blueprint
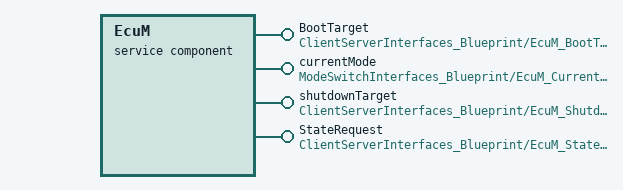
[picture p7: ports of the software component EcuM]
  service sw component type EcuM
    4 x provide port:
      BootTarget: provided-interface=ClientServerInterfaces_Blueprint/EcuM_BootTarget  # Provides an interface to SW-Cs to select a new boot target and query the current boot target.
      currentMode: provided-interface=ModeSwitchInterfaces_Blueprint/EcuM_CurrentMode  # Provides an interface to SW-Cs to get notified about state changes of the ECU.
      shutdownTarget: provided-interface=ClientServerInterfaces_Blueprint/EcuM_ShutdownTarget  # Provides an interface to SW-Cs to select a new shutdown target and query the current shutdown target.
      StateRequest: provided-interface=ClientServerInterfaces_Blueprint/EcuM_StateRequest  # Provides an interface to SW-Cs to request state changes of the ECU state. The port uses port-defined argument values to identify the user.
    behavior EcuMInternalBehavior: port-api-option{port-defined-argument-value{value=undefined, value-type=EcuM_UserType}, port=EcuM/StateRequest}
package /AUTOSAR/EcuM/ModeDeclarationGroups_Blueprint
  mode declaration group EcuM_Mode: category=ALPHABETIC_ORDER, initial-mode=EcuM_Mode/STARTUP
    6 x mode:
      POST_RUN
      RUN
      SHUTDOWN
      SLEEP
      STARTUP
      WAKE_SLEEP
package /AUTOSAR/EcuM/ModeSwitchInterfaces_Blueprint
  mode switch interface EcuM_CurrentMode: is-service=true  # Interface to read the current ECU mode
    mode group currentMode: type=ModeDeclarationGroups_Blueprint/EcuM_Mode
package /AUTOSAR/WdgM/ClientServerInterfaces_Blueprint
  client server interface WdgM_GlobalSupervision: is-service=true
    5 x operation:
      GetFirstExpiredSEID: possible-error=[WdgM_GlobalSupervision/E_OK, WdgM_GlobalSupervision/E_NOT_OK]  # Returns SEID that first reached the state WDGM_LOCAL_STATUS_EXPIRED.
        arg SEID: type=WdgM_SupervisedEntityIdType, direction=OUT  # Identifier of the supervised entity that first reached the state WDGM_LOCAL_STATUS_EXPIRED.
      GetGlobalStatus: possible-error=[WdgM_GlobalSupervision/E_OK, WdgM_GlobalSupervision/E_NOT_OK]  # Returns the global supervision status of the Watchdog Manager.
        arg Status: type=WdgM_GlobalStatusType, direction=OUT  # Global supervision status of the Watchdog Manager.
      GetMode: possible-error=[WdgM_GlobalSupervision/E_OK, WdgM_GlobalSupervision/E_NOT_OK]  # Returns the current mode of the Watchdog Manager.
        arg Mode: type=WdgM_ModeType, direction=OUT  # Current mode of the Watchdog Manager.
      PerformReset  # Instructs the Watchdog Manager to cause a watchdog reset.
      SetMode: possible-error=[WdgM_GlobalSupervision/E_OK, WdgM_GlobalSupervision/E_NOT_OK]  # Sets the current mode of Watchdog Manager.
        arg Mode: type=WdgM_ModeType, direction=IN  # One of the configured Watchdog Manager modes.
    error E_OK: error-code=0  # Operation successful
    error E_NOT_OK: error-code=1  # Operation failed
  client server interface WdgM_LocalSupervision: is-service=true
    operation CheckpointReached: possible-error=[WdgM_LocalSupervision/E_OK, WdgM_LocalSupervision/E_NOT_OK]  # Indicates to the Watchdog Manager that a Checkpoint within a Supervised Entity has been reached.
    error E_OK: error-code=0  # Operation successful
    error E_NOT_OK: error-code=1  # Operation failed
  client server interface WdgM_LocalSupervisionStatus: is-service=true
    operation GetLocalStatus: possible-error=[WdgM_LocalSupervisionStatus/E_OK, WdgM_LocalSupervisionStatus/E_NOT_OK]  # Returns the supervision status of an individual Supervised Entity.
      arg Status: type=WdgM_LocalStatusType, direction=OUT  # Supervision status of the given supervised entity.
    error E_OK: error-code=0  # Operation successful
    error E_NOT_OK: error-code=1  # Operation failed
package /AUTOSAR/WdgM/ServiceSwComponentTypes_Blueprint
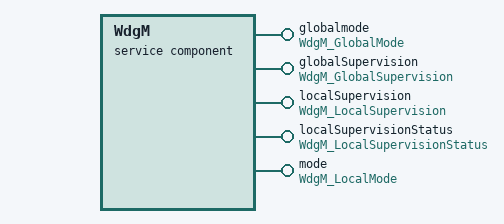
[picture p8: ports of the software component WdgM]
  service sw component type WdgM
    5 x provide port:
      globalmode: provided-interface=WdgM_GlobalMode
      globalSupervision: provided-interface=WdgM_GlobalSupervision  # This port provides the Global Supervision interface of the WdgM.
      localSupervision: provided-interface=WdgM_LocalSupervision  # This port provides the Supervision interface of one Supervised Entity Checkpoint to a SWC.
      localSupervisionStatus: provided-interface=WdgM_LocalSupervisionStatus  # This port provides the Supervision status interface of one Supervised Entity to a SWC.
      mode: provided-interface=WdgM_LocalMode
    behavior WdgMInternalBehavior
      port-api-options:
        {port-arg-values=[{value=undefined, value-type=WdgM_SupervisedEntityIdType}, {value=undefined, value-type=WdgM_CheckpointIdType}], port=localSupervision}
        {port-defined-argument-value{value=undefined, value-type=WdgM_SupervisedEntityIdType}, port=localSupervisionStatus}
package /AUTOSAR/WdgM/ModeDeclarationGroups_Blueprint
  mode declaration group WdgM_Mode: category=EXPLICIT_ORDER, initial-mode=SUPERVISION_OK, on-transition-value=255
    5 x mode:
      SUPERVISION_OK: value=0
      SUPERVISION_FAILED: value=1
      SUPERVISION_EXPIRED: value=2
      SUPERVISION_STOPPED: value=3
      SUPERVISION_DEACTIVATED: value=4
package /AUTOSAR/WdgM/ModeSwitchInterfaces_Blueprint
  mode switch interface WdgM_GlobalMode: is-service=true
    mode group currentMode: type=WdgM_Mode
  mode switch interface WdgM_LocalMode: is-service=true
    mode group currentMode: type=WdgM_Mode
package /AUTOSAR/BswM/ServiceSwComponentTypes_Blueprint
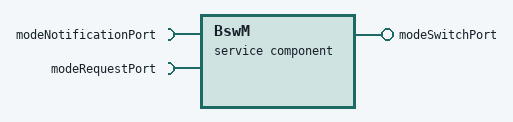
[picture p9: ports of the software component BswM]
  service sw component type BswM
    require port modeNotificationPort
    require port modeRequestPort
    provide port modeSwitchPort
    behavior BswMInternalBehavior
package /AUTOSAR/Os/ClientServerInterfaces_Blueprint
  client server interface OsService: variation-point={short-label=OsService, blueprint-condition=p=l-1=({ecuc(Os/OsCounter/OsSecondsPerTick)} != NULL)}, is-service=true
    operation GetCounterValue: possible-error=[OsService/E_OK, E_OS_ID]  # This service reads the current count value of a counter (returning either the hardware timer ticks if counter is driven by hardware or the software ticks when user drives counter).
      arg Value: type=TimeInMicrosecondsType, direction=OUT  # Contains the current tick value of the counter
    operation GetElapsedValue: possible-error=[OsService/E_OK, E_OS_ID, E_OS_VALUE]  # This service gets the number of ticks between the current tick value and a previously read tick value.
      arg Value: type=TimeInMicrosecondsType, direction=INOUT  # in: the previously read tick value of the counter out: the current tick value of the counter
      arg ElapsedValue: type=TimeInMicrosecondsType, direction=OUT  # The difference to the previous read value
    5 x error:
      E_OK: error-code=0  # Operation successful
      E_OS_ACCESS: error-code=1
      E_OS_ID: error-code=3
      E_OS_STATE: error-code=7
      E_OS_VALUE: error-code=8
package /AUTOSAR/Os/ServiceSwComponentTypes_Blueprint
  service sw component type Os
    provide port OsService: provided-interface=OsService
    behavior OsInternalBehavior: port-api-option{port-defined-argument-value{value=undefined, value-type=CounterType}, port=OsService}
package /AUTOSAR/StbM/ClientServerInterfaces_Blueprint
  5 x client server interface, all with is-service=true:
    GlobalTime_Master: variation-point={short-label=GlobalTime_Master, blueprint-condition=p=l-1=(({ecuc(StbM/StbMSynchronizedTimeBase/StbMIsSystemWideGlobalTimeMaster)} == TRUE ) || ({ecuc(StbM/StbMSynchronizedTimeBase/StbMAllowSystemWideGlobalTimeMaster)} == TRUE ))&& ({ecuc(StbM/StbMSynchronizedTimeBase/StbMSynchronizedTimeBaseIdentifier)} < 128)}
      7 x operation, all with possible-error=[GlobalTime_Master/E_OK, GlobalTime_Master/E_NOT_OK]:
        GetMasterConfig: variation-point=blueprint-condition=p=l-1={ecuc(StbM/StbMSynchronizedTimeBase/StbMAllowSystemWideGlobalTimeMaster)} != NULL  # Indicates in postbuild use case, if the StbM is actually configured as system wide master
          arg masterConfig: type=StbM_MasterConfigType, direction=OUT
        SetGlobalTime  # Allows the Customers to set the Global Time that will be sent to the buses and modify HW registers behind the providers, if supported. This function will be used if a Time Master is present in this ECU. Using SetGlobalTimecan lead to an immediate transmission of the Global Time.
          arg timeStamp: type=StbM_TimeStampType, direction=IN
          arg userData: type=StbM_UserDataType, direction=IN
        SetOffset: variation-point=blueprint-condition=p=l-1={ecuc(StbM/StbMSynchronizedTimeBase/StbMSynchronizedTimeBaseIdentifier)} > 15 &&{ecuc(StbM/StbMSynchronizedTimeBase/StbMSynchronizedTimeBaseIdentifier)} < 32  # Allows the Customers and the Timesync Modules to set the Offset Time.
          arg timeStamp: type=StbM_TimeStampType, direction=IN
          arg userData: type=StbM_UserDataType, direction=IN
        SetRateCorrection  # Allows to set the rate of a Synchronized Time Base (being either a Pure Local Time Base or not).
          arg rateDeviation: type=StbM_RateDeviationType, direction=IN  # Value of the applied rate deviation
        SetUserData  # Allows the Customers to set the User Data that will be sent to the buses.
          arg userData: type=StbM_UserDataType, direction=IN  # New user data
        TriggerTimeTransmission: variation-point=blueprint-condition=p=l-1={ecuc(StbM/StbMSynchronizedTimeBase/StbMSynchronizedTimeBaseIdentifier)} < 32  # Allows the Customers to force the Timesync Modules to transmit the current Time Base due to an incremented timeBaseUpdateCounter
        UpdateGlobalTime  # Allows the Customers to set the Global Time that will be sent to the buses and modify HW registers behind the providers, if supported. This function will be used if a Time Master is present in this ECU. Using UpdateGlobalTime will not lead to an immediate transmission of the Global Time.
          arg timeStamp: type=StbM_TimeStampType, direction=IN
          arg userData: type=StbM_UserDataType, direction=IN
      error E_OK: error-code=0  # Operation successful
      error E_NOT_OK: error-code=1  # Operation failed
    MeasurementNotification: variation-point={short-label=MeasurementNotification, blueprint-condition=p=l-1=(ecuc(StbM/StbMGeneral/StbMTimeRecordingSupport)} == True) &&({ecuc(StbM/StbMSynchronizedTimeBase/StbMSynchronizedTimeBaseIdentifier)} < 32)}  # Notifies about the availability of a new recorded measurement data block belonging to the Time Base.
      operation SetOffsetTimeRecordTable: possible-error=[MeasurementNotification/E_OK, MeasurementNotification/E_NOT_OK], variation-point=blueprint-condition=p=l-1={ecuc(StbM/StbMSynchronizedTimeBase/StbMSynchronizedTimeBaseIdentifier)} > 15 &&{ecuc(StbM/StbMSynchronizedTimeBase/StbMSynchronizedTimeBaseIdentifier)} < 32  # Provides to the recorded snapshot data Block of the table belonging to the Offset Time Base.
        arg offsetRecordTableBlock: type=StbM_OffsetRecordTableBlockType, direction=IN  # Header of the table
      operation SetSyncTimeRecordTable: possible-error=[MeasurementNotification/E_OK, MeasurementNotification/E_NOT_OK], variation-point=blueprint-condition=p=l-1={ecuc(StbM/StbMSynchronizedTimeBase/StbMSynchronizedTimeBaseIdentifier)} < 16  # Provides the recorded snapshot data Block of the table belonging to the Synchronized Time Base.
        arg syncRecordTableBlock: type=StbM_SyncRecordTableBlockType, direction=IN  # Block of the table
      error E_OK: error-code=0  # Operation successful
      error E_NOT_OK: error-code=1  # Operation failed
    GlobalTime_Slave: variation-point={short-label=GlobalTime_Slave, blueprint-condition=p=l-1={ecuc(StbM/StbMSynchronizedTimeBase/StbMSynchronizedTimeBaseIdentifier)} < 128}
      7 x operation, all with possible-error=[GlobalTime_Slave/E_OK, GlobalTime_Slave/E_NOT_OK]:
        GetCurrentTime  # Returns a time value (Local Time Base derived from Global Time Base) in standard format.
          arg timeStamp: type=StbM_TimeStampType, direction=OUT
          arg userData: type=StbM_UserDataType, direction=OUT
        GetCurrentTimeExtended: variation-point=blueprint-condition=p=l-1={ecuc(StbM/StbMGeneral/StbMGetCurrentTimeExtendedAvailable)}  # Returns a time value (Local Time Base derived from Global Time Base) in extended format.
          arg timeStamp: type=StbM_TimeStampExtendedType, direction=OUT
          arg userData: type=StbM_UserDataType, direction=OUT
        GetOffsetTimeRecordHead: variation-point=blueprint-condition=p=l-1=(({ecuc(StbM/StbMSynchronizedTimeBase/StbMIsSystemWideGlobalTimeMaster)} == FALSE) &&({ecuc(StbM/StbMSynchronizedTimeBase/StbMAllowSystemWideGlobalTimeMaster)} == FALSE)) &&({ecuc(StbM/StbMGeneral/StbMTimeRecordingSupport)} == True) &&({ecuc(StbM/StbMSynchronizedTimeBase/StbMSynchronizedTimeBaseIdentifier)} > 15) && {ecuc(StbM/StbMSynchronizedTimeBase/StbMSynchronizedTimeBaseIdentifier)} < 32  # Reads the header of the table with recorded measurement data belonging to the Offset Time Base
          arg offsetRecordTableHead: type=StbM_OffsetRecordTableHeadType, direction=OUT  # Header of the table
        GetRateDeviation  # Returns value of the current rate deviation of a Time Base
          arg rateDeviation: type=StbM_RateDeviationType, direction=OUT  # Value of the current rate deviation of a Time Base
        GetSyncTimeRecordHead: variation-point=blueprint-condition=p=l-1=(({ecuc(StbM/StbMSynchronizedTimeBase/StbMIsSystemWideGlobalTimeMaster)} == FALSE) &&({ecuc(StbM/StbMSynchronizedTimeBase/StbMAllowSystemWideGlobalTimeMaster)} == FALSE)) &&({ecuc(StbM/StbMGeneral/StbMTimeRecordingSupport)} == True) &&({ecuc(StbM/StbMSynchronizedTimeBase/StbMSynchronizedTimeBaseIdentifier)} < 16)  # Reads the header of the table with recorded measurement data belonging to the Synchronized Time Base
          arg syncRecordTableHead: type=StbM_SyncRecordTableHeadType, direction=OUT  # Header of the table
        GetTimeBaseStatus  # Returns detailed status information for a Synchronized (or Pure Local) Time Base and, if called for an Offset Time Base, for the Offset Time Base and the underlying Synchronized Time Base.
          arg syncTimeBaseStatus: type=StbM_TimeBaseStatusType, direction=OUT  # Status of the Synchronized (or Pure Local) Time Base
          arg offsetTimeBaseStatus: type=StbM_TimeBaseStatusType, direction=OUT  # Status of the Offset Time Base.
        GetTimeLeap: variation-point=blueprint-condition=p=l-1={ecuc(StbM/StbMSynchronizedTimeBase/StbMSynchronizedTimeBaseIdentifier)} < 32  # Returns value of time leap.
          arg timeJump: type=StbM_TimeDiffType, direction=OUT  # Time leap value
      error E_OK: error-code=0  # Operation successful
      error E_NOT_OK: error-code=1  # Operation failed
    TimeNotification: variation-point={short-label=TimeNotification, blueprint-condition=p=l-1=--}  # Notification, which indicates, that the timer has expired, which has been set by StartTimer
      operation NotifyTime: possible-error=[TimeNotification/E_OK, TimeNotification/E_NOT_OK]  # Notification, which indicates, that the timer has expired, which has been set by StbM_StartTimer
        arg deviationTime: type=StbM_TimeDiffType, direction=IN
      error E_OK: error-code=0  # Operation successful
      error E_NOT_OK: error-code=1  # Operation failed
    StartTimer: variation-point={short-label=StartTimer, blueprint-condition=p=l-1=--}  # Interface, which starts a timer for a Time Base
      operation StartTimer: possible-error=[StartTimer/E_OK, StartTimer/E_NOT_OK]  # Starts a StbM internal timer, which expires at the given expireTime and which triggers a time notification callback.
        arg expireTime: type=StbM_TimeStampType, direction=IN
      error E_OK: error-code=0  # Operation successful
      error E_NOT_OK: error-code=1  # Operation failed
package /AUTOSAR/StbM/SenderReceiverInterfaces_Blueprint
  sender receiver interface StatusNotification: variation-point={short-label=StatusNotification, blueprint-condition=p=l-1=--}  # Notification about a Time Base related status change
    data eventNotification: implementation-data-type=StbM_TimeBaseNotificationType
package /AUTOSAR/StbM/ServiceSwComponentTypes_Blueprint
  service sw component type StbM
    provide port GlobalTime_Master: variation-point=blueprint-condition=p=l-1=(({ecuc(StbM/StbMSynchronizedTimeBase/StbMIsSystemWideGlobalTimeMaster)} == TRUE ) ||({ecuc(StbM/StbMSynchronizedTimeBase/StbMAllowSystemWideGlobalTimeMaster)} == TRUE ))&&({ecuc(StbM/StbMSynchronizedTimeBase/StbMSynchronizedTimeBaseIdentifier)} < 128), provided-interface=GlobalTime_Master
    require port GlobalTime_Measurement: variation-point=blueprint-condition=p=l-1=(({ecuc(StbM/StbMSynchronizedTimeBase/StbMIsSystemWideGlobalTimeMaster)} == FALSE) &&({ecuc(StbM/StbMSynchronizedTimeBase/StbMAllowSystemWideGlobalTimeMaster)} == FALSE)) &&({ecuc(StbM/StbMGeneral/StbMTimeRecordingSupport)} == True) &&({ecuc(StbM/StbMSynchronizedTimeBase/StbMSynchronizedTimeBaseIdentifier)} < 32), required-interface=MeasurementNotification
    provide port GlobalTime_Slave: provided-interface=GlobalTime_Slave
    provide port GlobalTime_StatusEvent: variation-point=blueprint-condition=p=l-1=(({ecuc(StbM/StbMSynchronizedTimeBase/StbMNotificationInterface)} == SR_INTERFACE|| {ecuc(StbM/StbMSynchronizedTimeBase/StbMNotificationInterface)} == CALLBACK_AND_SR_INTERFACE))&& ({ecuc(StbM/StbMSynchronizedTimeBase/StbMSynchronizedTimeBaseIdentifier)} < 128), provided-interface=StatusNotification
    require port GlobalTime_TimeEvent: variation-point=blueprint-condition=p=l-1=({ecuc(StbM/StbMSynchronizedTimeBase/StbMNotificationCustomer/StbMTimeNotificationCallback)}==NULL) && ({ecuc(StbM/StbMSynchronizedTimeBase/StbMSynchronizedTimeBaseIdentifier)} < 128), required-interface=TimeNotification
    provide port StbM_StartTimer: variation-point=blueprint-condition=p=l-1={ecuc(StbM/StbMSynchronizedTimeBase/StbMSynchronizedTimeBaseIdentifier)} < 128, provided-interface=StartTimer
    behavior StbMInternalBehavior
      port-api-options:
        {port-defined-argument-value{value=undefined, value-type=StbM_SynchronizedTimeBaseType}, port=GlobalTime_Master}
        {port-defined-argument-value{value=undefined, value-type=StbM_SynchronizedTimeBaseType}, port=GlobalTime_Slave}
        {port-arg-values=[{value=undefined, value-type=StbM_SynchronizedTimeBaseType}, {value=undefined, value-type=StbM_CustomerIdType}], port=StbM_StartTimer}
package /AUTOSAR/KeyM/ClientServerInterfaces_Blueprint
  6 x client server interface, all with is-service=true:
    KeyMCertificateNotification  # This service interface provides callbacks for certificate management operation.
      operation CertificateVerifyCallbackNotification  # Notifies the application that a certificate verification has been finished.
        arg Result: type=KeyM_CertificateStatusType, direction=IN  # Contains information about the result of the operation.
      operation ServiceCertificateCallbackNotification  # Notifies the application that the certificate service operation has been finished. This function is used by the certificate submodule. This callback is only provided if KeyMServiceCertificateFunctionEnabled is set to TRUE.
        arg Result: type=KeyM_ResultType, direction=IN  # Contains information about the result of the operation.
        arg ResponseDataLength: type=uint16, direction=IN
        arg ResponseData: type=KeyM_CryptoKeyDataType, direction=IN  # Data returned by this operation
    KeyMCertificate  # Service of Certificate sub module
      4 x operation:
        GetCertificate: possible-error=[KeyMCertificate/E_OK, KeyMCertificate/E_NOT_OK, KeyMCertificate/KEYM_E_KEY_CERT_SIZE_MISMATCH, KeyMCertificate/KEYM_E_PARAMETER_MISMATCH, KEYM_E_KEY_CERT_READ_FAIL, KeyMCertificate/KEYM_E_KEY_CERT_EMPTY]  # Read certificate data from the certificate sub module
          arg Certificate: type=KeyM_CertificateType, direction=OUT
        GetStatus: possible-error=[KeyMCertificate/E_OK, KeyMCertificate/E_NOT_OK]  # Provides the status of a certificate.
          arg Status: type=KeyM_CertificateStatusType, direction=OUT  # Provides the status type.
        SetCertificate: possible-error=[KeyMCertificate/E_OK, KeyMCertificate/E_NOT_OK, KeyMCertificate/KEYM_E_KEY_CERT_SIZE_MISMATCH, KeyMCertificate/KEYM_E_PARAMETER_MISMATCH, KEYM_E_KEY_CERT_WRITE_FAIL]  # Provides certificate data to be processed by the certificate sub module
          arg Certificate: type=KeyM_CertificateType, direction=IN  # Certificate data
        VerifyCertificate: possible-error=[KeyMCertificate/E_OK, KeyMCertificate/E_NOT_OK, KeyMCertificate/KEYM_E_BUSY, KeyMCertificate/KEYM_E_KEY_CERT_SIZE_MISMATCH, KeyMCertificate/KEYM_E_PARAMETER_MISMATCH, KeyMCertificate/KEYM_E_KEY_CERT_EMPTY, KEYM_E_CERT_INVALID_CHAIN_OF_TRUST]  # Verify certificate data from the certificate sub module
      9 x error:
        E_OK: error-code=0
        E_NOT_OK: error-code=1
        KEYM_E_BUSY: error-code=2
        KEYM_E_KEY_CERT_SIZE_MISMATCH: error-code=4
        KEYM_E_PARAMETER_MISMATCH: error-code=5
        KEYM_E_KEY_CERT_WRITE_FAIL: error-code=7
        KEYM_E_KEY_CERT_READ_FAIL: error-code=9
        KEYM_E_KEY_CERT_EMPTY: error-code=10
        KEYM_E_CERT_INVALID_CHAIN_OF_TRUST: error-code=11
    KeyMCertificateElement  # Service of the certificate sub module to access certificate elements.
      operation CertificateElementGet: possible-error=[KeyMCertificateElement/E_OK, KeyMCertificateElement/E_NOT_OK, KeyMCertificateElement/KEYM_E_KEY_CERT_SIZE_MISMATCH, KeyMCertificateElement/KEYM_E_PARAMETER_MISMATCH, KeyMCertificateElement/KEYM_E_CERT_INVALID, KeyMCertificateElement/KEYM_E_KEY_CERT_EMPTY]  # Provides the content of a specific certificate element. The certificate configuration defines how the certificate submodule can find the element, e.g. by providing the object identifier (OID). This function is used to retrieve this information if only one element is assigned to the respective OID.
        arg CertificateElementData: type=KeyM_CertificateElementType, direction=OUT
        arg CertificateDataLength: type=uint32, direction=OUT
      operation CertificateElementGetByIndex: possible-error=[KeyMCertificateElement/E_OK, KeyMCertificateElement/E_NOT_OK, KeyMCertificateElement/KEYM_E_KEY_CERT_SIZE_MISMATCH, KeyMCertificateElement/KEYM_E_PARAMETER_MISMATCH, KeyMCertificateElement/KEYM_E_CERT_INVALID, KeyMCertificateElement/KEYM_E_KEY_CERT_EMPTY]  # This operation provides data from a specific certificate element.
        arg Index: type=uint16, direction=IN  # This is the index to dedicated element in the list
        arg CertificateElementData: type=KeyM_CertificateElementType, direction=OUT
        arg CertificateDataLength: type=uint32, direction=OUT
      operation CertificateElementGetCount: possible-error=[KeyMCertificateElement/E_OK, KeyMCertificateElement/E_NOT_OK, KeyMCertificateElement/KEYM_E_KEY_CERT_SIZE_MISMATCH, KeyMCertificateElement/KEYM_E_PARAMETER_MISMATCH, KeyMCertificateElement/KEYM_E_CERT_INVALID, KeyMCertificateElement/KEYM_E_KEY_CERT_EMPTY]  # This operation returns the amount of items available for a certificate element.
        arg count: type=uint16, direction=OUT  # Number of items available for an element
      6 x error:
        E_OK: error-code=0
        E_NOT_OK: error-code=1
        KEYM_E_KEY_CERT_SIZE_MISMATCH: error-code=4
        KEYM_E_PARAMETER_MISMATCH: error-code=5
        KEYM_E_CERT_INVALID: error-code=6
        KEYM_E_KEY_CERT_EMPTY: error-code=10
    KeyMCertificateService  # Service of root and intermediate certificates
      operation Service: possible-error=[KeyMCertificateService/E_OK, KeyMCertificateService/E_NOT_OK, KeyMCertificateService/KEYM_E_KEY_CERT_SIZE_MISMATCH, KeyMCertificateService/KEYM_E_PARAMETER_MISMATCH], variation-point=blueprint-condition=p=l-1={ecuc(KeyM/KeyMGeneral/KeyMServiceCertificateFunctionEnabled)} == true  # Allows to perform service operations for certificates
        7 x arg:
          Operation: type=KeyM_ServiceCertificateType, direction=IN  # Defines the type of service operation.
          CertificateName: type=KeyM_KeyCertNameDataType, direction=IN  # Provides the name of the certificate the service shall be applied to.
          CertificateNameLength: type=uint16, direction=IN
          RequestData: type=KeyM_DataPtr, direction=IN  # Information that comes along with the request, e.g. certificate
          RequestDataLength: type=uint16, direction=IN
          ResponseData: type=KeyM_DataPtr, direction=OUT  # Data returned by this operation
          ResponseDataLength: type=uint16, direction=OUT
      4 x error:
        E_OK: error-code=0
        E_NOT_OK: error-code=1
        KEYM_E_KEY_CERT_SIZE_MISMATCH: error-code=4
        KEYM_E_PARAMETER_MISMATCH: error-code=5
    KeyMCryptoKey  # Service of CryptoKey sub module
      5 x operation:
        Finalize: possible-error=[KeyMCryptoKey/E_OK, KeyMCryptoKey/E_NOT_OK, KeyMCryptoKey/KEYM_E_KEY_CERT_SIZE_MISMATCH, KeyMCryptoKey/KEYM_E_PARAMETER_MISMATCH], variation-point=blueprint-condition=p=l-1={ecuc(KeyM/KeyMGeneral/KeyMCryptoKeyHandlerStartFinalizeEnabled)} == true
          4 x arg:
            RequestData: type=KeyM_CryptoKeyDataType, direction=IN  # Information that comes along with the request, e.g. signature
            RequestDataLength: type=uint16, direction=IN
            ResponseData: type=KeyM_CryptoKeyDataType, direction=OUT  # Data returned by this operation
            ResponseDataLength: type=uint16, direction=OUT
        Prepare: possible-error=[KeyMCryptoKey/E_OK, KeyMCryptoKey/E_NOT_OK, KeyMCryptoKey/KEYM_E_KEY_CERT_SIZE_MISMATCH, KeyMCryptoKey/KEYM_E_PARAMETER_MISMATCH], variation-point=blueprint-condition=p=l-1={ecuc(KeyM/KeyMGeneral/KeyMCryptoKeyPrepareFunctionEnabled)} == true
          4 x arg:
            RequestData: type=KeyM_CryptoKeyDataType, direction=IN  # Information that comes along with the request, e.g. signature
            RequestDataLength: type=uint16, direction=IN
            ResponseData: type=KeyM_CryptoKeyDataType, direction=OUT  # Data returned by this operation
            ResponseDataLength: type=uint16, direction=OUT
        Start: possible-error=[KeyMCryptoKey/E_OK, KeyMCryptoKey/E_NOT_OK, KeyMCryptoKey/KEYM_E_KEY_CERT_SIZE_MISMATCH, KeyMCryptoKey/KEYM_E_PARAMETER_MISMATCH], variation-point=blueprint-condition=p=l-1={ecuc(KeyM/KeyMGeneral/KeyMCryptoKeyHandlerStartFinalizeEnabled)} == true  # This function intents to start a key update operation.
          5 x arg:
            StartType: type=KeyM_StartType, direction=IN  # Defines in which mode the key operation shall be executed
            RequestData: type=KeyM_CryptoKeyDataType, direction=IN  # Information that comes along with the request, e.g. signature
            RequestDataLength: type=uint16, direction=IN
            ResponseData: type=KeyM_CryptoKeyDataType, direction=OUT  # Data returned by this operation
            ResponseDataLength: type=uint16, direction=OUT
        Update: possible-error=[KeyMCryptoKey/E_OK, KeyMCryptoKey/E_NOT_OK, KeyMCryptoKey/KEYM_E_KEY_CERT_SIZE_MISMATCH, KeyMCryptoKey/KEYM_E_PARAMETER_MISMATCH]
          6 x arg:
            KeyName: type=KeyM_KeyCertNameDataType, direction=IN  # Provides the name of the key that shall be verified
            KeyNameLength: type=uint16, direction=IN
            RequestData: type=KeyM_CryptoKeyDataType, direction=IN  # Information that comes along with the request, e.g. signature
            RequestDataLength: type=uint16, direction=IN
            ResponseData: type=KeyM_CryptoKeyDataType, direction=OUT  # Data returned by this operation
            ResponseDataLength: type=uint16, direction=OUT
        Verify: possible-error=[KeyMCryptoKey/E_OK, KeyMCryptoKey/E_NOT_OK, KeyMCryptoKey/KEYM_E_BUSY, KEYM_E_PENDING, KeyMCryptoKey/KEYM_E_KEY_CERT_SIZE_MISMATCH, KeyMCryptoKey/KEYM_E_PARAMETER_MISMATCH, KeyMCryptoKey/KEYM_E_CERT_INVALID, KeyMCryptoKey/KEYM_E_KEY_CERT_EMPTY], variation-point=blueprint-condition=p=l-1={ecuc(KeyM/KeyMGeneral/KeyMCryptoKeyVerifyFunctionEnabled)} == true  # The intention is to perform a verification of input data using an assigned crypto job with its key.
          6 x arg:
            KeyName: type=KeyM_KeyCertNameDataType, direction=IN  # Provides the name of the key that shall be verified
            KeyNameLength: type=uint16, direction=IN
            RequestData: type=KeyM_CryptoKeyDataType, direction=IN  # Information that comes along with the request, e.g. signature
            RequestDataLength: type=uint16, direction=IN
            ResponseData: type=KeyM_CryptoKeyDataType, direction=OUT  # Data returned by this operation
            ResponseDataLength: type=uint16, direction=OUT
      8 x error:
        E_OK: error-code=0
        E_NOT_OK: error-code=1
        KEYM_E_BUSY: error-code=2
        KEYM_E_PENDING: error-code=3
        KEYM_E_KEY_CERT_SIZE_MISMATCH: error-code=4
        KEYM_E_PARAMETER_MISMATCH: error-code=5
        KEYM_E_CERT_INVALID: error-code=6
        KEYM_E_KEY_CERT_EMPTY: error-code=10
    KeyMCryptoKeyNotification  # Service of <module>
      operation CryptoKeyFinalizeCallbackNotification: variation-point=blueprint-condition=p=l-1={ecuc(KeyM/KeyMGeneral/KeyMCryptoKeyStartFinalizeFunctionEnabled)} == true  # Notifies the application that a crypto key finalize operation has been finished. The callback function is only called and needed if KeyMCryptoKeyStartFinalizeFunctionEnabled is set to TRUE.
        arg Result: type=KeyM_ResultType, direction=IN  # Contains information about the result of the operation.
        arg ResponseDataLength: type=uint16, direction=IN
        arg ResponseData: type=KeyM_CryptoKeyDataType, direction=IN  # Data returned by this operation
      operation CryptoKeyUpdateCallbackNotification  # Notifies the application that a crypto key update operation has been finished. This function is used by the key manager.
        arg Result: type=KeyM_ResultType, direction=IN  # Contains information about the result of the operation.
        arg ResponseDataLength: type=uint16, direction=IN
        arg ResponseData: type=KeyM_CryptoKeyDataType, direction=IN  # Data returned by this operation
      operation CryptoKeyVerifyCallbackNotification  # Notifies the application that a crypto key verify operation has been finished. This function is used by the key manager.
        4 x arg, all with direction=IN:
          Result: type=KeyM_ResultType  # Contains information about the result of the operation.
          KeyId: type=uint32  # The key identifier where this verification was started for.
          ResultDataLength: type=uint16
          ResultData: type=KeyM_CryptoKeyDataType  # Data returned by this operation
package /AUTOSAR/KeyM/ServiceSwComponentTypes_Blueprint
  service sw component type KeyM
    require port KeyM_CertificateNotification: variation-point=blueprint-condition=p=l-1=KeyMCertificateVerifyCallbackNotificationFunc == NULL, required-interface=KeyMCertificateNotification  # Port to execute certificate notification related functions.
    5 x provide port:
      KeyMCertificate: provided-interface=KeyMCertificate  # Port to execute certificate related functions.
      KeyMCertificateElement: provided-interface=KeyMCertificateElement  # Port to execute certificate related functions.
      KeyMCertificateService: provided-interface=KeyMCertificateService  # Port to execute root and intermediate certificate related function.
      KeyMCryptoKey: provided-interface=KeyMCryptoKey  # Port to execute crypto key related functions.
      KeyMCryptoKeyNotification: provided-interface=KeyMCryptoKeyNotification  # Port to execute crypto key notification related functions.
    behavior KeyMInternalBehavior
      port-api-options:
        {port-defined-argument-value{value=undefined, value-type=KeyM_CertificateIdType}, port=KeyM_CertificateNotification}
        {port-defined-argument-value{value=undefined, value-type=KeyM_CertificateIdType}, port=KeyMCertificate}
        {port-arg-values=[{value=undefined, value-type=KeyM_CertificateIdType}, {value=undefined, value-type=KeyM_CertElementIdType}], port=KeyMCertificateElement}
package /AUTOSAR/Csm/ClientServerInterfaces_Blueprint
  30 x client server interface, all with is-service=true:
    CallbackNotification  # Interface for the callback notification.
      operation CallbackNotification  # Notifies the application with a return value that the job has finished.
        arg result: type=Csm_ResultType, direction=IN  # Return value that shall be returned to the application
    AsyncJobInterface  # Asynchronous processing interface to execute the hash calculation.
      operation CancelJob: possible-error=[AsyncJobInterface/E_OK, AsyncJobInterface/E_NOT_OK, AsyncJobInterface/CSM_E_JOB_CANCELED]  # Cancels the job.
      operation Hash: possible-error=[AsyncJobInterface/E_OK, AsyncJobInterface/E_NOT_OK, AsyncJobInterface/CSM_E_BUSY, AsyncJobInterface/CSM_E_SMALL_BUFFER]  # Utilize the random seed service.
        4 x arg:
          dataBuffer: type=Csm_DataPtr, direction=IN  # References the data to be hashed.
          dataLength: type=uint32, direction=IN  # Contains the length in bytes of the data to be hashed.
          resultBuffer: type=Csm_DataPtr, direction=IN  # References the data of the hash.
          resultLength: type=uint32, direction=INOUT  # Contains the length in bytes of the hash.
      5 x error:
        E_OK: error-code=0  # Operation successful
        E_NOT_OK: error-code=1  # Operation failed
        CSM_E_BUSY: error-code=2  # Request failed, service is still busy.
        CSM_E_SMALL_BUFFER: error-code=3  # The provided buffer is too small to store the result.
        CSM_E_JOB_CANCELED: error-code=12  # Request failed because the job has been canceled.
    AsyncJobInterface  # Asynchronous processing interface to execute the MAC generation.
      operation CancelJob: possible-error=[AsyncJobInterface/E_OK, AsyncJobInterface/E_NOT_OK, AsyncJobInterface/CSM_E_JOB_CANCELED]  # Cancels the job.
      operation MacGenerate: possible-error=[AsyncJobInterface/E_OK, AsyncJobInterface/E_NOT_OK, AsyncJobInterface/CSM_E_BUSY, AsyncJobInterface/CSM_E_SMALL_BUFFER, AsyncJobInterface/CSM_E_KEY_NOT_VALID, AsyncJobInterface/CSM_E_KEY_SIZE_MISMATCH, AsyncJobInterface/CSM_E_KEY_EMPTY]  # Uses the given data to perform a MAC generation and stores the MAC in the memory location pointed to by the MAC pointer.
        4 x arg:
          dataBuffer: type=Csm_DataPtr, direction=IN  # References the data from which a MAC shall be generated of.
          dataLength: type=uint32, direction=IN  # Contains the length in bytes of the data from which a MAC shall be generated of.
          resultBuffer: type=Csm_DataPtr, direction=OUT  # References the data of the MAC.
          resultLength: type=uint32, direction=INOUT  # Contains the length in bytes of the MAC.
      8 x error:
        E_OK: error-code=0  # Operation successful
        E_NOT_OK: error-code=1  # Operation failed
        CSM_E_BUSY: error-code=2  # Request failed, service is still busy.
        CSM_E_SMALL_BUFFER: error-code=3  # The provided buffer is too small to store the result.
        CSM_E_KEY_NOT_VALID: error-code=9  # Request failed, the key is not valid.
        CSM_E_KEY_SIZE_MISMATCH: error-code=10  # Request failed because the key element is not partially accessible and the provided key element length is too short or too long for that key element.
        CSM_E_JOB_CANCELED: error-code=12  # Request failed because the job has been canceled.
        CSM_E_KEY_EMPTY: error-code=13  # The service request failed because of uninitialized source key element.
    AsyncJobInterface  # Asynchronous processing interface to execute the MAC verification.
      operation CancelJob: possible-error=[AsyncJobInterface/E_OK, AsyncJobInterface/E_NOT_OK, AsyncJobInterface/CSM_E_JOB_CANCELED]  # Cancels the job.
      operation MacVerify: possible-error=[AsyncJobInterface/E_OK, AsyncJobInterface/E_NOT_OK, AsyncJobInterface/CSM_E_BUSY, AsyncJobInterface/CSM_E_SMALL_BUFFER, AsyncJobInterface/CSM_E_KEY_NOT_VALID, AsyncJobInterface/CSM_E_KEY_SIZE_MISMATCH, AsyncJobInterface/CSM_E_KEY_EMPTY]  # Uses the given data to perform a MAC generation and stores the MAC in the memory location pointed to by the MAC pointer.
        5 x arg:
          dataBuffer: type=Csm_DataPtr, direction=IN  # References the data from which a MAC shall be generated of.
          dataLength: type=uint32, direction=IN  # Contains the length in bytes of the data for whichs MAC shall be verified.
          compareBuffer: type=Csm_DataPtr, direction=IN  # References the MAC to be verified.
          compareLength: type=uint32, direction=IN  # Contains the length in BITS of the MAC to be verified.
          resultBuffer: type=Crypto_VerifyResultType, direction=OUT  # Contains the verification result.
      8 x error:
        E_OK: error-code=0  # Operation successful
        E_NOT_OK: error-code=1  # Operation failed
        CSM_E_BUSY: error-code=2  # Request failed, service is still busy.
        CSM_E_SMALL_BUFFER: error-code=3  # The provided buffer is too small to store the result.
        CSM_E_KEY_NOT_VALID: error-code=9  # Request failed, the key is not valid.
        CSM_E_KEY_SIZE_MISMATCH: error-code=10  # Request failed because the key element is not partially accessible and the provided key element length is too short or too long for that key element.
        CSM_E_JOB_CANCELED: error-code=12  # Request failed because the job has been canceled.
        CSM_E_KEY_EMPTY: error-code=13  # The service request failed because of uninitialized source key element.
    AsyncJobInterface  # Asynchronous processing interface to execute the encryption.
      operation CancelJob: possible-error=[AsyncJobInterface/E_OK, AsyncJobInterface/E_NOT_OK, AsyncJobInterface/CSM_E_JOB_CANCELED]  # Cancels the job.
      operation Encrypt: possible-error=[AsyncJobInterface/E_OK, AsyncJobInterface/E_NOT_OK, AsyncJobInterface/CSM_E_BUSY, AsyncJobInterface/CSM_E_SMALL_BUFFER, AsyncJobInterface/CSM_E_KEY_NOT_VALID, AsyncJobInterface/CSM_E_KEY_SIZE_MISMATCH, AsyncJobInterface/CSM_E_KEY_EMPTY]  # Encrypts the given data and stores the ciphertext in the memory location pointed by the result pointer.
        4 x arg:
          dataBuffer: type=Csm_DataPtr, direction=IN  # References the data to be encrypted.
          dataLength: type=uint32, direction=IN  # Contains the length in bytes of the data to be encrypted.
          result: type=Csm_DataPtr, direction=OUT  # References the data of the cipher.
          resultLength: type=uint32, direction=INOUT  # Contains the length in bytes of the cipher.
      8 x error:
        E_OK: error-code=0  # Operation successful
        E_NOT_OK: error-code=1  # Operation failed
        CSM_E_BUSY: error-code=2  # Request failed, service is still busy.
        CSM_E_SMALL_BUFFER: error-code=3  # The provided buffer is too small to store the result.
        CSM_E_KEY_NOT_VALID: error-code=9  # Request failed, the key is not valid.
        CSM_E_KEY_SIZE_MISMATCH: error-code=10  # Request failed because the key element is not partially accessible and the provided key element length is too short or too long for that key element.
        CSM_E_JOB_CANCELED: error-code=12  # Request failed because the job has been canceled.
        CSM_E_KEY_EMPTY: error-code=13  # The service request failed because of uninitialized source key element.
    AsyncJobInterface  # Asynchronous processing interface to execute the decryption.
      operation CancelJob: possible-error=[AsyncJobInterface/E_OK, AsyncJobInterface/E_NOT_OK, AsyncJobInterface/CSM_E_JOB_CANCELED]  # Cancels the job.
      operation Decrypt: possible-error=[AsyncJobInterface/E_OK, AsyncJobInterface/E_NOT_OK, AsyncJobInterface/CSM_E_BUSY, AsyncJobInterface/CSM_E_SMALL_BUFFER, AsyncJobInterface/CSM_E_KEY_NOT_VALID, AsyncJobInterface/CSM_E_KEY_SIZE_MISMATCH, AsyncJobInterface/CSM_E_KEY_EMPTY]  # Decrypts the given data and stores the plaintext in the memory location pointed by the resultBuffer pointer.
        4 x arg:
          dataBuffer: type=Csm_DataPtr, direction=IN  # References the data to be decrypted.
          dataLength: type=uint32, direction=IN  # Contains the length in bytes of the data to be decrypted.
          resultBuffer: type=Csm_DataPtr, direction=OUT  # References the data of the decrypted plaintext.
          resultLength: type=uint32, direction=INOUT  # Contains the length in bytes of the decrypted plaintext.
      8 x error:
        E_OK: error-code=0  # Operation successful
        E_NOT_OK: error-code=1  # Operation failed
        CSM_E_BUSY: error-code=2  # Request failed, service is still busy.
        CSM_E_SMALL_BUFFER: error-code=3  # The provided buffer is too small to store the result.
        CSM_E_KEY_NOT_VALID: error-code=9  # Request failed, the key is not valid.
        CSM_E_KEY_SIZE_MISMATCH: error-code=10  # Request failed because the key element is not partially accessible and the provided key element length is too short or too long for that key element.
        CSM_E_JOB_CANCELED: error-code=12  # Request failed because the job has been canceled.
        CSM_E_KEY_EMPTY: error-code=13  # The service request failed because of uninitialized source key element.
    AsyncJobInterface  # Asynchronous processing interface to execute the AEAD encryption.
      operation AEADEncrypt: possible-error=[AsyncJobInterface/E_OK, AsyncJobInterface/E_NOT_OK, AsyncJobInterface/CSM_E_BUSY, AsyncJobInterface/CSM_E_SMALL_BUFFER, AsyncJobInterface/CSM_E_KEY_NOT_VALID, AsyncJobInterface/CSM_E_KEY_SIZE_MISMATCH, AsyncJobInterface/CSM_E_KEY_EMPTY]  # Streaming approach of the AEAD encryption.
        8 x arg:
          plaintextBuffer: type=Csm_DataPtr, direction=IN  # References the plaintext to be encrypted with AEAD.
          plaintextLength: type=uint32, direction=IN  # This element Contains the length in bytes of the plaintext to be encrypted with AEAD.
          associatedDataBuffer: type=Csm_DataPtr, direction=IN  # References the data of the header (that is not part of the encryption but authentication).
          associatedDataLength: type=uint32, direction=IN  # Contains the length in bytes of the data of the header.
          ciphertextBuffer: type=Csm_DataPtr, direction=OUT  # References the data of the AEAD cipher.
          ciphertextLengthPtr: type=uint32, direction=INOUT  # Contains the length in bytes of the data of the AEAD cipher.
          tagBuffer: type=Csm_DataPtr, direction=OUT  # References the data of the Tag.
          tagLength: type=uint32, direction=INOUT  # Contains the length in bytes of the data of the Tag.
      operation CancelJob: possible-error=[AsyncJobInterface/E_OK, AsyncJobInterface/E_NOT_OK, AsyncJobInterface/CSM_E_JOB_CANCELED]  # Cancels the job.
      8 x error:
        E_OK: error-code=0  # Operation successful
        E_NOT_OK: error-code=1  # Operation failed
        CSM_E_BUSY: error-code=2  # Request failed, service is still busy.
        CSM_E_SMALL_BUFFER: error-code=3  # The provided buffer is too small to store the result.
        CSM_E_KEY_NOT_VALID: error-code=9  # Request failed, the key is not valid.
        CSM_E_KEY_SIZE_MISMATCH: error-code=10  # Request failed because the key element is not partially accessible and the provided key element length is too short or too long for that key element.
        CSM_E_JOB_CANCELED: error-code=12  # Request failed because the job has been canceled.
        CSM_E_KEY_EMPTY: error-code=13  # The service request failed because of uninitialized source key element.
    AsyncJobInterface  # Asynchronous processing interface to execute the AEAD decryption.
      operation AEADDecrypt: possible-error=[AsyncJobInterface/E_OK, AsyncJobInterface/E_NOT_OK, AsyncJobInterface/CSM_E_BUSY, AsyncJobInterface/CSM_E_SMALL_BUFFER, AsyncJobInterface/CSM_E_KEY_NOT_VALID, AsyncJobInterface/CSM_E_KEY_SIZE_MISMATCH, AsyncJobInterface/CSM_E_KEY_EMPTY]  # Streaming approach of the AEAD decryption.
        9 x arg:
          ciphertextBuffer: type=Csm_DataPtr, direction=IN  # References the ciphertext to be decrypted with AEAD.
          ciphertextLength: type=uint32, direction=IN  # Contains the length in bytes of the ciphertext to be decrypted with AEAD.
          associatedDataBuffer: type=Csm_DataPtr, direction=IN  # References the data of the header (that is not part of the encryption but authentication).
          associatedDataLength: type=uint32, direction=IN  # Contains the length in bytes of the data of the header.
          tagBuffer: type=Csm_DataPtr, direction=IN  # References the data of the Tag.
          tagLength: type=uint32, direction=IN  # Contains the length in BITS of the data of the Tag.
          plaintextBuffer: type=Csm_DataPtr, direction=OUT  # References the data of the decrypted AEAD plaintext.
          plaintextLength: type=uint32, direction=INOUT  # Contains the length in bytes of the data of the decrypted AEAD plaintext.
          resultBuffer: type=Crypto_VerifyResultType, direction=OUT  # Contains the verification result.
      operation CancelJob: possible-error=[AsyncJobInterface/E_OK, AsyncJobInterface/E_NOT_OK, AsyncJobInterface/CSM_E_JOB_CANCELED]  # Cancels the job.
      8 x error:
        E_OK: error-code=0  # Operation successful
        E_NOT_OK: error-code=1  # Operation failed
        CSM_E_BUSY: error-code=2  # Request failed, service is still busy.
        CSM_E_SMALL_BUFFER: error-code=3  # The provided buffer is too small to store the result.
        CSM_E_KEY_NOT_VALID: error-code=9  # Request failed, the key is not valid.
        CSM_E_KEY_SIZE_MISMATCH: error-code=10  # Request failed because the key element is not partially accessible and the provided key element length is too short or too long for that key element.
        CSM_E_JOB_CANCELED: error-code=12  # Request failed because the job has been canceled.
        CSM_E_KEY_EMPTY: error-code=13  # The service request failed because of uninitialized source key element.
    AsyncJobInterface  # Asynchronous processing interface to generate a signature.
      operation CancelJob: possible-error=[AsyncJobInterface/E_OK, AsyncJobInterface/E_NOT_OK, AsyncJobInterface/CSM_E_JOB_CANCELED]  # Cancels the job.
      operation SignatureGenerate: possible-error=[AsyncJobInterface/E_OK, AsyncJobInterface/E_NOT_OK, AsyncJobInterface/CSM_E_BUSY, AsyncJobInterface/CSM_E_SMALL_BUFFER, AsyncJobInterface/CSM_E_KEY_NOT_VALID, AsyncJobInterface/CSM_E_KEY_SIZE_MISMATCH, AsyncJobInterface/CSM_E_KEY_EMPTY]  # Operation to generate a signature.
        4 x arg:
          dataBuffer: type=Csm_DataPtr, direction=IN  # References the data from which the signature shall be generated.
          dataLength: type=uint32, direction=IN  # Contains the length in bytes of the data from which the signature shall be generated.
          resultBuffer: type=Csm_DataPtr, direction=OUT  # References the signature.
          resultLength: type=uint32, direction=INOUT  # Contains the length in bytes of the signature.
      8 x error:
        E_OK: error-code=0  # Operation successful
        E_NOT_OK: error-code=1  # Operation failed
        CSM_E_BUSY: error-code=2  # Request failed, service is still busy.
        CSM_E_SMALL_BUFFER: error-code=3  # The provided buffer is too small to store the result.
        CSM_E_KEY_NOT_VALID: error-code=9  # Request failed, the key is not valid.
        CSM_E_KEY_SIZE_MISMATCH: error-code=10  # Request failed because the key element is not partially accessible and the provided key element length is too short or too long for that key element.
        CSM_E_JOB_CANCELED: error-code=12  # Request failed because the job has been canceled.
        CSM_E_KEY_EMPTY: error-code=13  # The service request failed because of uninitialized source key element.
    AsyncJobInterface  # Asynchronous processing interface to execute the signature verification.
      operation CancelJob: possible-error=[AsyncJobInterface/E_OK, AsyncJobInterface/E_NOT_OK, AsyncJobInterface/CSM_E_JOB_CANCELED]  # Cancels the job.
      operation SignatureVerify: possible-error=[AsyncJobInterface/E_OK, AsyncJobInterface/E_NOT_OK, AsyncJobInterface/CSM_E_BUSY, AsyncJobInterface/CSM_E_SMALL_BUFFER, AsyncJobInterface/CSM_E_KEY_NOT_VALID, AsyncJobInterface/CSM_E_KEY_SIZE_MISMATCH, AsyncJobInterface/CSM_E_KEY_EMPTY]  # Operation to verify a signature.
        5 x arg:
          dataBuffer: type=Csm_DataPtr, direction=IN  # References the data for which signature shall be verified.
          dataLength: type=uint32, direction=IN  # Contains the length in bytes of the data for which signature shall be verified.
          compareBuffer: type=Csm_DataPtr, direction=IN  # References the signature to be verified.
          compareLength: type=uint32, direction=IN  # Contains the length in bytes of the signature to be verified.
          resultBuffer: type=Crypto_VerifyResultType, direction=OUT  # Contains the verification result.
      8 x error:
        E_OK: error-code=0  # Operation successful
        E_NOT_OK: error-code=1  # Operation failed
        CSM_E_BUSY: error-code=2  # Request failed, service is still busy.
        CSM_E_SMALL_BUFFER: error-code=3  # The provided buffer is too small to store the result.
        CSM_E_KEY_NOT_VALID: error-code=9  # Request failed, the key is not valid.
        CSM_E_KEY_SIZE_MISMATCH: error-code=10  # Request failed because the key element is not partially accessible and the provided key element length is too short or too long for that key element.
        CSM_E_JOB_CANCELED: error-code=12  # Request failed because the job has been canceled.
        CSM_E_KEY_EMPTY: error-code=13  # The service request failed because of uninitialized source key element.
    AsyncJobInterface  # Asynchronous processing interface to execute the random number generation.
      operation CancelJob: possible-error=[AsyncJobInterface/E_OK, AsyncJobInterface/E_NOT_OK, AsyncJobInterface/CSM_E_JOB_CANCELED]  # Cancels the job.
      operation RandomGenerate: possible-error=[AsyncJobInterface/E_OK, AsyncJobInterface/E_NOT_OK, AsyncJobInterface/CSM_E_BUSY, AsyncJobInterface/CSM_E_ENTROPY_EXHAUSTION]  # Generates a random number and stores it in the memory location pointed by the resultBuffer pointer.
        arg resultBuffer: type=Csm_DataPtr, direction=OUT  # References the random number.
        arg resultLength: type=uint32, direction=INOUT  # Contains the length in bytes of the data of random number.
      5 x error:
        E_OK: error-code=0  # Operation successful
        E_NOT_OK: error-code=1  # Operation failed
        CSM_E_BUSY: error-code=2  # Request failed, service is still busy.
        CSM_E_ENTROPY_EXHAUSTION: error-code=4  # Request failed, entropy of random number generator is exhausted.
        CSM_E_JOB_CANCELED: error-code=12  # Request failed because the job has been canceled.
    AsyncJobInterface  # Interface to execute certificate parsing.
      operation CancelJob: possible-error=[AsyncJobInterface/E_OK, AsyncJobInterface/E_NOT_OK, AsyncJobInterface/CSM_E_JOB_CANCELED]  # Cancels the job.
      operation CertificateParse: possible-error=[AsyncJobInterface/E_OK, AsyncJobInterface/E_NOT_OK, AsyncJobInterface/CSM_E_BUSY, AsyncJobInterface/CSM_E_KEY_EMPTY]  # This function shall dispatch the certificate parse function to the CRYIF.
        arg key: type=uint32, direction=IN  # Identifier of the key.
      5 x error:
        E_OK: error-code=0  # Operation successful
        E_NOT_OK: error-code=1  # Operation failed
        CSM_E_BUSY: error-code=2  # Request failed, service is still busy.
        CSM_E_JOB_CANCELED: error-code=12  # Request failed because the job has been canceled.
        CSM_E_KEY_EMPTY: error-code=13  # The service request failed because of uninitialized source key element.
    AsyncJobInterface  # Interface to execute certificate verification.
      operation CancelJob: possible-error=[AsyncJobInterface/E_OK, AsyncJobInterface/E_NOT_OK, AsyncJobInterface/CSM_E_JOB_CANCELED]  # Cancels the job.
      operation CertificateVerify: possible-error=[AsyncJobInterface/E_OK, AsyncJobInterface/E_NOT_OK, AsyncJobInterface/CSM_E_BUSY, AsyncJobInterface/CSM_E_KEY_EMPTY]  # Verifies the certificate stored in the key referenced by verifyKeyId with the certificate stored in the key referenced by keyId. Note: Only certificates stored in the same Crypto Driver can be verified against each other. If the key element CRYPTO_KE_CERTIFICATE_CURRENT_TIME is used for the verification of the validity period of the certificate identified by verifyKeyId, it shall have the same format as the timestamp in the certificate.
        arg key: type=uint32, direction=IN  # Identifier of the key.
        arg verifyKeyId: type=uint32, direction=IN  # Holds the identifier of the key containing the certificate to be verified.
        arg verifyPtr: type=Crypto_VerifyResultType, direction=OUT  # Contains the result of the certificate verification.
      5 x error:
        E_OK: error-code=0  # Operation successful
        E_NOT_OK: error-code=1  # Operation failed
        CSM_E_BUSY: error-code=2  # Request failed, service is still busy.
        CSM_E_JOB_CANCELED: error-code=12  # Request failed because the job has been canceled.
        CSM_E_KEY_EMPTY: error-code=13  # The service request failed because of uninitialized source key element.
    AsyncJobInterface  # Interface to execute key derive.
      operation CancelJob: possible-error=[AsyncJobInterface/E_OK, AsyncJobInterface/E_NOT_OK, AsyncJobInterface/CSM_E_JOB_CANCELED]  # Cancels the job.
      operation KeyDerive: possible-error=[AsyncJobInterface/E_OK, AsyncJobInterface/E_NOT_OK, AsyncJobInterface/CSM_E_BUSY, AsyncJobInterface/CSM_E_KEY_READ_FAIL, AsyncJobInterface/CSM_E_KEY_WRITE_FAIL, AsyncJobInterface/CSM_E_KEY_SIZE_MISMATCH, AsyncJobInterface/CSM_E_KEY_EMPTY]  # Derives a new key by using the key elements in the given key. The given key contains the key elements for the password and salt. The derived key is stored in the key element with the id 1 of the key identified by targetCryptoKeyId.
        arg key: type=uint32, direction=IN  # Identifier of the key.
        arg targetKeyId: type=uint32, direction=IN  # Holds the identifier of the key which is used to store the derived key.
      8 x error:
        E_OK: error-code=0  # Operation successful
        E_NOT_OK: error-code=1  # Operation failed
        CSM_E_BUSY: error-code=2  # Request failed, service is still busy.
        CSM_E_KEY_READ_FAIL: error-code=6  # The service request failed because read access was denied.
        CSM_E_KEY_WRITE_FAIL: error-code=7  # The service request failed because write access was denied.
        CSM_E_KEY_SIZE_MISMATCH: error-code=10  # Request failed because the key element is not partially accessible and the provided key element length is too short or too long for that key element.
        CSM_E_JOB_CANCELED: error-code=12  # Request failed because the job has been canceled.
        CSM_E_KEY_EMPTY: error-code=13  # The service request failed because of uninitialized source key element.
    AsyncJobInterface  # Interface to execute calculation of the public value for key exchange.
      operation CancelJob: possible-error=[AsyncJobInterface/E_OK, AsyncJobInterface/E_NOT_OK, AsyncJobInterface/CSM_E_JOB_CANCELED]  # Cancels the job.
      operation KeyExchangeCalcPubVal: possible-error=[AsyncJobInterface/E_OK, AsyncJobInterface/E_NOT_OK, AsyncJobInterface/CSM_E_BUSY, AsyncJobInterface/CSM_E_SMALL_BUFFER, AsyncJobInterface/CSM_E_KEY_EMPTY]  # Calculates the public value of the current user for the key exchange and stores the public key in the provided buffer.
        arg key: type=uint32, direction=IN  # Identifier of the key.
        arg publicValuePtr: type=Csm_DataPtr, direction=OUT  # Holds a pointer to the memory location in which the public value length in bytes is stored. On calling this function, this parameter shall contain the size of the buffer in bytes provided by publicValuePtr. When the request has finished, the actual length of the returned value shall be stored.
        arg publicValueLengthPtr: type=uint32, direction=OUT  # Contains the pointer to the data where the public value shall be stored.
      6 x error:
        E_OK: error-code=0  # Operation successful
        E_NOT_OK: error-code=1  # Operation failed
        CSM_E_BUSY: error-code=2  # Request failed, service is still busy.
        CSM_E_SMALL_BUFFER: error-code=3  # The provided buffer is too small to store the result.
        CSM_E_JOB_CANCELED: error-code=12  # Request failed because the job has been canceled.
        CSM_E_KEY_EMPTY: error-code=13  # The service request failed because of uninitialized source key element.
    AsyncJobInterface  # Interface to execute calculation of shared secret for key exchange.
      operation CancelJob: possible-error=[AsyncJobInterface/E_OK, AsyncJobInterface/E_NOT_OK, AsyncJobInterface/CSM_E_JOB_CANCELED]  # Cancels the job.
      operation KeyExchangeCalcSecret: possible-error=[AsyncJobInterface/E_OK, AsyncJobInterface/E_NOT_OK, AsyncJobInterface/CSM_E_BUSY, AsyncJobInterface/CSM_E_SMALL_BUFFER, AsyncJobInterface/CSM_E_KEY_EMPTY]  # Calculates the shared secret key for the key exchange with the key material of the key identified by the keyId and the partner public key. The shared secret key is stored as a key element in the same key.
        arg key: type=uint32, direction=IN  # Identifier of the key.
        arg partnerPublicValuePtr: type=Csm_DataPtr, direction=IN  # Holds the pointer to the memory location containing the partner's public value.
        arg partnerPublicValueLength: type=uint32, direction=OUT  # Contains the number of bytes of the partner public value.
      6 x error:
        E_OK: error-code=0  # Operation successful
        E_NOT_OK: error-code=1  # Operation failed
        CSM_E_BUSY: error-code=2  # Request failed, service is still busy.
        CSM_E_SMALL_BUFFER: error-code=3  # The provided buffer is too small to store the result.
        CSM_E_JOB_CANCELED: error-code=12  # Request failed because the job has been canceled.
        CSM_E_KEY_EMPTY: error-code=13  # The service request failed because of uninitialized source key element.
    AsyncJobInterface  # Interface to execute key generation.
      operation CancelJob: possible-error=[AsyncJobInterface/E_OK, AsyncJobInterface/E_NOT_OK, AsyncJobInterface/CSM_E_JOB_CANCELED]  # Cancels the job.
      operation KeyGenerate: possible-error=[AsyncJobInterface/E_OK, AsyncJobInterface/E_NOT_OK, AsyncJobInterface/CSM_E_BUSY, AsyncJobInterface/CSM_E_KEY_EMPTY]  # Generates new key material and stores it in the key identified by keyId.
        arg key: type=uint32, direction=IN  # Identifier of the key.
      5 x error:
        E_OK: error-code=0  # Operation successful
        E_NOT_OK: error-code=1  # Operation failed
        CSM_E_BUSY: error-code=2  # Request failed, service is still busy.
        CSM_E_JOB_CANCELED: error-code=12  # Request failed because the job has been canceled.
        CSM_E_KEY_EMPTY: error-code=13  # The service request failed because of uninitialized source key element.
    AsyncJobInterface  # Interface to set a key valid.
      operation CancelJob: possible-error=[AsyncJobInterface/E_OK, AsyncJobInterface/E_NOT_OK, AsyncJobInterface/CSM_E_JOB_CANCELED]  # Cancels the job.
      operation KeySetValid: possible-error=[AsyncJobInterface/E_OK, AsyncJobInterface/E_NOT_OK, AsyncJobInterface/CSM_E_BUSY]  # Operation to set a key valid.
        arg key: type=uint32, direction=IN  # Identifier of the key.
      4 x error:
        E_OK: error-code=0  # Operation successful
        E_NOT_OK: error-code=1  # Operation failed
        CSM_E_BUSY: error-code=2  # Request failed, service is still busy.
        CSM_E_JOB_CANCELED: error-code=12  # Request failed because the job has been canceled.
    AsyncJobInterface  # Interface to random seed operation.
      operation CancelJob: possible-error=[AsyncJobInterface/E_OK, AsyncJobInterface/E_NOT_OK, AsyncJobInterface/CSM_E_JOB_CANCELED]  # Cancels the job.
      operation RandomSeed: possible-error=[AsyncJobInterface/E_OK, AsyncJobInterface/E_NOT_OK, AsyncJobInterface/CSM_E_BUSY]  # Utilize the random seed service.
        arg key: type=uint32, direction=IN  # Identifier of the key.
        arg seedPtr: type=Csm_DataPtr, direction=IN  # Holds the data which shall be used for the random seed initialization.
        arg seedLength: type=uint32, direction=IN  # Contains the length of the seed in bytes.
      4 x error:
        E_OK: error-code=0  # Operation successful
        E_NOT_OK: error-code=1  # Operation failed
        CSM_E_BUSY: error-code=2  # Request failed, service is still busy.
        CSM_E_JOB_CANCELED: error-code=12  # Request failed because the job has been canceled.
    SyncJobInterface  # Synchronous processing interface to execute the hash calculation.
      operation Hash: possible-error=[SyncJobInterface/E_OK, SyncJobInterface/E_NOT_OK, SyncJobInterface/CSM_E_BUSY, SyncJobInterface/CSM_E_SMALL_BUFFER]  # Streaming approach of the hash calculation.
        4 x arg:
          dataBuffer: type=Csm_HashDataType, direction=IN  # Contains the data to be hashed.
          dataLength: type=uint32, direction=IN  # Contains the length in bytes of the data to be hashed.
          resultBuffer: type=Csm_HashResultType, direction=OUT  # Contains the data of the hash.
          resultLength: type=uint32, direction=INOUT  # Contains the length in bytes of the hash.
      4 x error:
        E_OK: error-code=0  # Operation successful
        E_NOT_OK: error-code=1  # Operation failed
        CSM_E_BUSY: error-code=2  # Request failed, service is still busy.
        CSM_E_SMALL_BUFFER: error-code=3  # The provided buffer is too small to store the result.
    SyncJobInterface  # Synchronous processing interface to execute the MAC generation.
      operation MacGenerate: possible-error=[SyncJobInterface/E_OK, SyncJobInterface/E_NOT_OK, SyncJobInterface/CSM_E_BUSY, SyncJobInterface/CSM_E_SMALL_BUFFER, SyncJobInterface/CSM_E_KEY_NOT_VALID, SyncJobInterface/CSM_E_KEY_SIZE_MISMATCH, SyncJobInterface/CSM_E_KEY_EMPTY]  # Uses the given data to perform a MAC generation and stores the MAC in the memory location pointed to by the MAC pointer.
        4 x arg:
          dataBuffer: type=Csm_MacGenerateDataType, direction=IN  # Contains the data from which a MAC shall be generated of.
          dataLength: type=uint32, direction=IN  # Contains the length in bytes of the data from which a MAC shall be generated of.
          resultBuffer: type=Csm_MacGenerateResultType, direction=OUT  # Contains the data of the MAC.
          resultLength: type=uint32, direction=INOUT  # Contains the length in bytes of the MAC.
      7 x error:
        E_OK: error-code=0  # Operation successful
        E_NOT_OK: error-code=1  # Operation failed
        CSM_E_BUSY: error-code=2  # Request failed, service is still busy.
        CSM_E_SMALL_BUFFER: error-code=3  # The provided buffer is too small to store the result.
        CSM_E_KEY_NOT_VALID: error-code=9  # Request failed, the key is not valid.
        CSM_E_KEY_SIZE_MISMATCH: error-code=10  # Request failed because the key element is not partially accessible and the provided key element length is too short or too long for that key element.
        CSM_E_KEY_EMPTY: error-code=13  # The service request failed because of uninitialized source key element.
    SyncJobInterface  # Synchronous processing interface to execute the MAC verification.
      operation MacVerify: possible-error=[SyncJobInterface/E_OK, SyncJobInterface/E_NOT_OK, SyncJobInterface/CSM_E_BUSY, SyncJobInterface/CSM_E_SMALL_BUFFER, SyncJobInterface/CSM_E_KEY_NOT_VALID, SyncJobInterface/CSM_E_KEY_SIZE_MISMATCH, SyncJobInterface/CSM_E_KEY_EMPTY]  # Uses the given data to perform a MAC generation and stores the MAC in the memory location pointed to by the MAC pointer.
        5 x arg:
          dataBuffer: type=Csm_MacVerifyDataType, direction=IN  # Contains the data from which a MAC shall be generated of.
          dataLength: type=uint32, direction=IN  # Contains the length in bytes of the data for whichs MAC shall be verified.
          compareBuffer: type=Csm_MacVerifyCompareType, direction=IN  # Contains the MAC to be verified.
          compareLength: type=uint32, direction=IN  # Contains the length in BITS of the MAC to be verified.
          resultBuffer: type=Crypto_VerifyResultType, direction=OUT  # Contains the verification result.
      7 x error:
        E_OK: error-code=0  # Operation successful
        E_NOT_OK: error-code=1  # Operation failed
        CSM_E_BUSY: error-code=2  # Request failed, service is still busy.
        CSM_E_SMALL_BUFFER: error-code=3  # The provided buffer is too small to store the result.
        CSM_E_KEY_NOT_VALID: error-code=9  # Request failed, the key is not valid.
        CSM_E_KEY_SIZE_MISMATCH: error-code=10  # Request failed because the key element is not partially accessible and the provided key element length is too short or too long for that key element.
        CSM_E_KEY_EMPTY: error-code=13  # The service request failed because of uninitialized source key element.
    SyncJobInterface  # Synchronous processing interface to execute the encryption.
      operation Encrypt: possible-error=[SyncJobInterface/E_OK, SyncJobInterface/E_NOT_OK, SyncJobInterface/CSM_E_BUSY, SyncJobInterface/CSM_E_SMALL_BUFFER, SyncJobInterface/CSM_E_KEY_NOT_VALID, SyncJobInterface/CSM_E_KEY_SIZE_MISMATCH, SyncJobInterface/CSM_E_KEY_EMPTY]  # Encrypts the given data and store the ciphertext in the memory location pointed by the result pointer.
        4 x arg:
          dataBuffer: type=Csm_EncryptDataType, direction=IN  # Contains the data to be encrypted.
          dataLength: type=uint32, direction=IN  # Contains the length in bytes of the data to be encrypted.
          result: type=Csm_EncryptResultType, direction=OUT  # Contains the data of the cipher.
          resultLength: type=uint32, direction=INOUT  # Contains the length in bytes of the cipher.
      7 x error:
        E_OK: error-code=0  # Operation successful
        E_NOT_OK: error-code=1  # Operation failed
        CSM_E_BUSY: error-code=2  # Request failed, service is still busy.
        CSM_E_SMALL_BUFFER: error-code=3  # The provided buffer is too small to store the result.
        CSM_E_KEY_NOT_VALID: error-code=9  # Request failed, the key is not valid.
        CSM_E_KEY_SIZE_MISMATCH: error-code=10  # Request failed because the key element is not partially accessible and the provided key element length is too short or too long for that key element.
        CSM_E_KEY_EMPTY: error-code=13  # The service request failed because of uninitialized source key element.
    SyncJobInterface  # Synchronous processing interface to execute the decryption.
      operation Decrypt: possible-error=[SyncJobInterface/E_OK, SyncJobInterface/E_NOT_OK, SyncJobInterface/CSM_E_BUSY, SyncJobInterface/CSM_E_SMALL_BUFFER, SyncJobInterface/CSM_E_KEY_NOT_VALID, SyncJobInterface/CSM_E_KEY_SIZE_MISMATCH, SyncJobInterface/CSM_E_KEY_EMPTY]  # Streaming approach of the decryption.
        4 x arg:
          dataBuffer: type=Csm_DecryptDataType, direction=IN  # Contains the data to be decrypted.
          dataLength: type=uint32, direction=IN  # Contains the length in bytes of the data to be decrypted.
          resultBuffer: type=Csm_DecryptResultType, direction=OUT  # Contains the data of the decrypted plaintext.
          resultLength: type=uint32, direction=INOUT  # Contains the length in bytes of the decrypted plaintext.
      7 x error:
        E_OK: error-code=0  # Operation successful
        E_NOT_OK: error-code=1  # Operation failed
        CSM_E_BUSY: error-code=2  # Request failed, service is still busy.
        CSM_E_SMALL_BUFFER: error-code=3  # The provided buffer is too small to store the result.
        CSM_E_KEY_NOT_VALID: error-code=9  # Request failed, the key is not valid.
        CSM_E_KEY_SIZE_MISMATCH: error-code=10  # Request failed because the key element is not partially accessible and the provided key element length is too short or too long for that key element.
        CSM_E_KEY_EMPTY: error-code=13  # The service request failed because of uninitialized source key element.
    SyncJobInterface  # Synchronous processing interface to execute the AEAD encryption.
      operation AEADEncrypt: possible-error=[SyncJobInterface/E_OK, SyncJobInterface/E_NOT_OK, SyncJobInterface/CSM_E_BUSY, SyncJobInterface/CSM_E_SMALL_BUFFER, SyncJobInterface/CSM_E_KEY_NOT_VALID, SyncJobInterface/CSM_E_KEY_SIZE_MISMATCH, SyncJobInterface/CSM_E_KEY_EMPTY]  # Streaming approach of the AEAD encryption.
        8 x arg:
          plaintextBuffer: type=Csm_AEADEncryptPlaintextType, direction=IN  # Contains the plaintext to be encrypted with AEAD.
          plaintextLength: type=uint32, direction=IN  # This element Contains the length in bytes of the plaintext to be encrypted with AEAD.
          associatedDataBuffer: type=Csm_AEADEncryptAssociatedDataType, direction=IN  # Contains the data of the header (that is not part of the encryption but authentication).
          associatedDataLength: type=uint32, direction=IN  # Contains the length in bytes of the data of the header.
          ciphertextBuffer: type=Csm_AEADEncryptCiphertextType, direction=OUT  # Contains the data of the AEAD cipher.
          ciphertextLengthPtr: type=uint32, direction=INOUT  # Contains the length in bytes of the data of the AEAD cipher.
          tagBuffer: type=Csm_AEADEncryptTagType, direction=OUT  # Contains the data of the Tag.
          tagLength: type=uint32, direction=INOUT  # Contains the length in bytes of the data of the Tag.
      7 x error:
        E_OK: error-code=0  # Operation successful
        E_NOT_OK: error-code=1  # Operation failed
        CSM_E_BUSY: error-code=2  # Request failed, service is still busy.
        CSM_E_SMALL_BUFFER: error-code=3  # The provided buffer is too small to store the result.
        CSM_E_KEY_NOT_VALID: error-code=9  # Request failed, the key is not valid.
        CSM_E_KEY_SIZE_MISMATCH: error-code=10  # Request failed because the key element is not partially accessible and the provided key element length is too short or too long for that key element.
        CSM_E_KEY_EMPTY: error-code=13  # The service request failed because of uninitialized source key element.
    SyncJobInterface  # Synchronous processing interface to execute the AEAD decryption.
      operation AEADDecrypt: possible-error=[SyncJobInterface/E_OK, SyncJobInterface/E_NOT_OK, SyncJobInterface/CSM_E_BUSY, SyncJobInterface/CSM_E_SMALL_BUFFER, SyncJobInterface/CSM_E_KEY_NOT_VALID, SyncJobInterface/CSM_E_KEY_SIZE_MISMATCH, SyncJobInterface/CSM_E_KEY_EMPTY]  # Streaming approach of the AEAD decryption.
        9 x arg:
          ciphertextBuffer: type=Csm_AEADDecryptCiphertextType, direction=IN  # Contains the ciphertext to be decrypted with AEAD.
          ciphertextLength: type=uint32, direction=IN  # Contains the length in bytes of the ciphertext to be decrypted with AEAD.
          associatedDataBuffer: type=Csm_AEADDecryptAssociatedDataType, direction=IN  # Contains the data of the header (that is not part of the encryption but authentication) .
          associatedDataLength: type=uint32, direction=IN  # Contains the length in bytes of the data of the header.
          tagBuffer: type=Csm_AEADDecryptTagType, direction=IN  # Contains the data of the Tag.
          tagLength: type=uint32, direction=IN  # Contains the length in BITS of the data of the Tag.
          plaintextBuffer: type=Csm_AEADDecryptPlaintextType, direction=OUT  # Contains the data of the decrypted AEAD plaintext.
          plaintextLength: type=uint32, direction=INOUT  # Contains the length in bytes of the data of the decrypted AEAD plaintext.
          resultBuffer: type=Crypto_VerifyResultType, direction=OUT  # Contains the verification result.
      7 x error:
        E_OK: error-code=0  # Operation successful
        E_NOT_OK: error-code=1  # Operation failed
        CSM_E_BUSY: error-code=2  # Request failed, service is still busy.
        CSM_E_SMALL_BUFFER: error-code=3  # The provided buffer is too small to store the result.
        CSM_E_KEY_NOT_VALID: error-code=9  # Request failed, the key is not valid.
        CSM_E_KEY_SIZE_MISMATCH: error-code=10  # Request failed because the key element is not partially accessible and the provided key element length is too short or too long for that key element.
        CSM_E_KEY_EMPTY: error-code=13  # The service request failed because of uninitialized source key element.
    SyncJobInterface  # Synchronous processing interface to generate a signature.
      operation SignatureGenerate: possible-error=[SyncJobInterface/E_OK, SyncJobInterface/E_NOT_OK, SyncJobInterface/CSM_E_BUSY, SyncJobInterface/CSM_E_SMALL_BUFFER, SyncJobInterface/CSM_E_KEY_NOT_VALID, SyncJobInterface/CSM_E_KEY_SIZE_MISMATCH, SyncJobInterface/CSM_E_KEY_EMPTY]  # Streaming approach of the signature generation.
        4 x arg:
          dataBuffer: type=Csm_SignatureGenerateDataType, direction=IN  # Contains the data from which the signature shall be generated.
          dataLength: type=uint32, direction=IN  # Contains the length in bytes of the data from which the signature shall be generated.
          resultBuffer: type=Csm_SignatureGenerateResultType, direction=OUT  # Contains the signature.
          resultLength: type=uint32, direction=INOUT  # Contains the length in bytes of the signature.
      7 x error:
        E_OK: error-code=0  # Operation successful
        E_NOT_OK: error-code=1  # Operation failed
        CSM_E_BUSY: error-code=2  # Request failed, service is still busy.
        CSM_E_SMALL_BUFFER: error-code=3  # The provided buffer is too small to store the result.
        CSM_E_KEY_NOT_VALID: error-code=9  # Request failed, the key is not valid.
        CSM_E_KEY_SIZE_MISMATCH: error-code=10  # Request failed because the key element is not partially accessible and the provided key element length is too short or too long for that key element.
        CSM_E_KEY_EMPTY: error-code=13  # The service request failed because of uninitialized source key element.
    SyncJobInterface  # Synchronous processing interface to execute the signature verification.
      operation SignatureVerify: possible-error=[SyncJobInterface/E_OK, SyncJobInterface/E_NOT_OK, SyncJobInterface/CSM_E_BUSY, SyncJobInterface/CSM_E_SMALL_BUFFER, SyncJobInterface/CSM_E_KEY_NOT_VALID, SyncJobInterface/CSM_E_KEY_SIZE_MISMATCH, SyncJobInterface/CSM_E_KEY_EMPTY]  # Interface to verify a signature.
        5 x arg:
          dataBuffer: type=Csm_SignatureVerifyDataType, direction=IN  # Contains the data for whichs signature shall be verified.
          dataLength: type=uint32, direction=IN  # Contains the length in bytes of the data for whichs signature shall be verified.
          compareBuffer: type=Csm_SignatureVerifyCompareType, direction=IN  # Contains the signature to be verified.
          compareLength: type=uint32, direction=IN  # Contains the length in bytes of the signature to be verified.
          resultBuffer: type=Crypto_VerifyResultType, direction=OUT  # Contains the verification result.
      7 x error:
        E_OK: error-code=0  # Operation successful
        E_NOT_OK: error-code=1  # Operation failed
        CSM_E_BUSY: error-code=2  # Request failed, service is still busy.
        CSM_E_SMALL_BUFFER: error-code=3  # The provided buffer is too small to store the result.
        CSM_E_KEY_NOT_VALID: error-code=9  # Request failed, the key is not valid.
        CSM_E_KEY_SIZE_MISMATCH: error-code=10  # Request failed because the key element is not partially accessible and the provided key element length is too short or too long for that key element.
        CSM_E_KEY_EMPTY: error-code=13  # The service request failed because of uninitialized source key element.
    SyncJobInterface  # Synchronous processing interface to execute the random number generation.
      operation RandomGenerate: possible-error=[SyncJobInterface/E_OK, SyncJobInterface/E_NOT_OK, SyncJobInterface/CSM_E_BUSY, SyncJobInterface/CSM_E_ENTROPY_EXHAUSTION]  # Synchronous processing interface to execute the random number generation.
        arg resultBuffer: type=Csm_RandomGenerateResultType, direction=OUT  # Contains the random number
        arg resultLength: type=uint32, direction=INOUT  # Contains the length in bytes of the data of random number.
      4 x error:
        E_OK: error-code=0  # Operation successful
        E_NOT_OK: error-code=1  # Operation failed
        CSM_E_BUSY: error-code=2  # Request failed, service is still busy.
        CSM_E_ENTROPY_EXHAUSTION: error-code=4  # Request failed, entropy of random number generator is exhausted.
    CsmKeyManagement: variation-point={short-label=CsmKeyManagement, blueprint-condition=p=l-1=({ecuc(Csm/CsmKeys/CsmKey.CsmKeyUsePort)} == TRUE)}  # Interface to execute the key management functions.
      13 x operation:
        CertificateParse: possible-error=[CsmKeyManagement/E_OK, CsmKeyManagement/E_NOT_OK, CsmKeyManagement/CSM_E_BUSY, CsmKeyManagement/CSM_E_KEY_EMPTY]  # This function shall dispatch the certificate parse function to the CRYIF.
        CertificateVerify: possible-error=[CsmKeyManagement/E_OK, CsmKeyManagement/E_NOT_OK, CsmKeyManagement/CSM_E_BUSY, CsmKeyManagement/CSM_E_KEY_EMPTY]  # Verifies the certificate stored in the key referenced by verifyKeyId with the certificate stored in the key referenced by keyId. Note: Only certificates stored in the same Crypto Driver can be verified against each other. If the key element CRYPTO_KE_CERTIFICATE_CURRENT_TIME is used for the verification of the validity period of the certificate indentified by verifyKeyId, it shall have the same format as the timestamp in the certificate
          arg verifyKeyId: type=uint32, direction=IN  # Holds the identifier of the key containing the certificate to be verified
          arg verifyPtr: type=Crypto_VerifyResultType, direction=OUT  # Contains the result of the certificate verification
        KeyCopy: possible-error=[CsmKeyManagement/E_OK, CsmKeyManagement/E_NOT_OK, CsmKeyManagement/CSM_E_BUSY, CsmKeyManagement/CSM_E_KEY_READ_FAIL, CsmKeyManagement/CSM_E_KEY_WRITE_FAIL, CSM_E_KEY_NOT_AVAILABLE, CsmKeyManagement/CSM_E_KEY_SIZE_MISMATCH, CsmKeyManagement/CSM_E_KEY_EMPTY]  # This function shall copy all key elements from the source key to a target key.
          arg targetKeyId: type=uint32, direction=IN  # Holds the identifier of the key whose key element shall be the destination element.
        KeyDerive: possible-error=[CsmKeyManagement/E_OK, CsmKeyManagement/E_NOT_OK, CsmKeyManagement/CSM_E_BUSY, CsmKeyManagement/CSM_E_KEY_READ_FAIL, CsmKeyManagement/CSM_E_KEY_WRITE_FAIL, CsmKeyManagement/CSM_E_KEY_SIZE_MISMATCH, CsmKeyManagement/CSM_E_KEY_EMPTY]  # Derives a new key by using the key elements in the given key. The given key contains the key elements for the password and salt. The derived key is stored in the key element with the id 1 of the key identified by targetCryptoKeyId.
          arg targetKeyId: type=uint32, direction=IN  # Holds the identifier of the key which is used to store the derived key.
        KeyElementCopy: possible-error=[CsmKeyManagement/E_OK, CsmKeyManagement/E_NOT_OK, CsmKeyManagement/CSM_E_BUSY, CsmKeyManagement/CSM_E_KEY_READ_FAIL, CsmKeyManagement/CSM_E_KEY_WRITE_FAIL, CSM_E_KEY_NOT_AVAILABLE, CsmKeyManagement/CSM_E_KEY_SIZE_MISMATCH, CsmKeyManagement/CSM_E_KEY_EMPTY]  # This function shall copy a key elements from one key to a target key
          arg keyElementId: type=uint32, direction=IN  # Holds the identifier of the key element which shall be the source for the copy operation.
          arg targetKeyId: type=uint32, direction=IN  # Holds the identifier of the key whose key element shall be the destination element.
          arg targetKeyElementId: type=uint32, direction=IN  # Holds the identifier of the key element which shall be the destination for the copy operation.
        KeyElementCopyPartial: possible-error=[CsmKeyManagement/E_OK, CsmKeyManagement/E_NOT_OK, CsmKeyManagement/CSM_E_BUSY, CsmKeyManagement/CSM_E_KEY_READ_FAIL, CsmKeyManagement/CSM_E_KEY_WRITE_FAIL, CSM_E_KEY_NOT_AVAILABLE, CsmKeyManagement/CSM_E_KEY_SIZE_MISMATCH, CsmKeyManagement/CSM_E_KEY_EMPTY]  # This function shall copy parts of a a key elements from one key to parts of a target key element of a target key.
          6 x arg, all with type=uint32, direction=IN:
            keyElementId  # Holds the identifier of the key element which shall be the source for the copy operation.
            keyElementSourceOffset  # This is the offset of the source key element indicating the start index of the copy operation.
            keyElementTargetOffset  # This is the offset of the destination key element indicating the start index of the copy operation.
            keyElementCopyLength  # Specifies the number of bytes that shall be copied.
            targetKeyId  # Holds the identifier of the key whose key element shall be the destination element.
            targetKeyElementId  # Holds the identifier of the key element which shall be the destination for the copy operation.
        KeyElementGet: possible-error=[CsmKeyManagement/E_OK, CsmKeyManagement/E_NOT_OK, CsmKeyManagement/CSM_E_BUSY, CsmKeyManagement/CSM_E_SMALL_BUFFER, CsmKeyManagement/CSM_E_KEY_READ_FAIL, CSM_E_KEY_NOT_AVAILABLE, CsmKeyManagement/CSM_E_KEY_EMPTY]  # Retrieves the key element bytes from a specific key element of the key and stores the key element in the provided buffer.
          arg keyElementId: type=uint32, direction=IN  # Holds the identifier of the key element to be read.
          arg keyPtr: type=Csm_KeyDataType, direction=OUT  # Holds the data to the key element bytes to be written.
          arg keyLength: type=uint32, direction=INOUT  # Contains the number of key element bytes.
        KeyElementSet: possible-error=[CsmKeyManagement/E_OK, CsmKeyManagement/E_NOT_OK, CsmKeyManagement/CSM_E_BUSY, CsmKeyManagement/CSM_E_KEY_WRITE_FAIL, CSM_E_KEY_NOT_AVAILABLE, CsmKeyManagement/CSM_E_KEY_SIZE_MISMATCH]  # Sets the given key element bytes to the key.
          arg keyElementId: type=uint32, direction=IN  # Holds the identifier of the key element to be written.
          arg keyPtr: type=Csm_KeyDataType, direction=IN  # Holds the data to the key element bytes to be processed.
          arg keyLength: type=uint32, direction=IN  # Contains the number of key element bytes.
        KeyExchangeCalcPubVal: possible-error=[CsmKeyManagement/E_OK, CsmKeyManagement/E_NOT_OK, CsmKeyManagement/CSM_E_BUSY, CsmKeyManagement/CSM_E_SMALL_BUFFER, CsmKeyManagement/CSM_E_KEY_EMPTY]  # Calculates the public value of the current user for the key exchange and stores the public key in the provided buffer
          arg publicValuePtr: type=Csm_DataPtr, direction=OUT  # Holds a pointer to the memory location in which the public value length in bytes is stored. On calling this function, this parameter shall contain the size of the buffer in bytes provided by publicValuePtr. When the request has finished, the actual length of the returned value shall be stored.
          arg publicValueLengthPtr: type=uint32, direction=INOUT  # Contains the pointer to the data where the public value shall be stored.
        KeyExchangeCalcSecret: possible-error=[CsmKeyManagement/E_OK, CsmKeyManagement/E_NOT_OK, CsmKeyManagement/CSM_E_BUSY, CsmKeyManagement/CSM_E_SMALL_BUFFER, CsmKeyManagement/CSM_E_KEY_EMPTY]  # Calculates the shared secret key for the key exchange with the key material of the key identified by the keyId and the partner public key. The shared secret key is stored as a key element in the same key.
          arg partnerPublicValuePtr: type=Csm_DataPtr, direction=IN  # Holds the pointer to the memory location containing the partner's public value
          arg partnerPublicValueLength: type=uint32, direction=IN  # Contains the number of bytes of the partner pulic value
        KeyGenerate: possible-error=[CsmKeyManagement/E_OK, CsmKeyManagement/E_NOT_OK, CsmKeyManagement/CSM_E_BUSY, CsmKeyManagement/CSM_E_KEY_EMPTY]  # Generates new key material and store it in the key identified by keyId.
        KeySetValid: possible-error=[CsmKeyManagement/E_OK, CsmKeyManagement/E_NOT_OK, CsmKeyManagement/CSM_E_BUSY]  # Sets the given key element bytes to the key.
        RandomSeed: possible-error=[CsmKeyManagement/E_OK, CsmKeyManagement/E_NOT_OK, CsmKeyManagement/CSM_E_BUSY]  # Feeds the key element CRYPTO_KE_RANDOM_SEED with a random seed.
          arg seedPtr: type=Csm_DataPtr, direction=IN  # Holds the data which shall be used for the random seed initialization.
          arg seedLength: type=uint32, direction=IN  # Contains the length of the seed in bytes.
      9 x error:
        E_OK: error-code=0  # Operation successful
        E_NOT_OK: error-code=1  # Operation failed
        CSM_E_BUSY: error-code=2  # Request failed, service is still busy.
        CSM_E_SMALL_BUFFER: error-code=3  # The provided buffer is too small to store the result.
        CSM_E_KEY_READ_FAIL: error-code=6  # The service request failed because read access was denied.
        CSM_E_KEY_WRITE_FAIL: error-code=7  # The service request failed because write access was denied.
        CSM_E_KEY_NOT_AVAILABLE: error-code=8  # The service request failed because the key is not available.
        CSM_E_KEY_SIZE_MISMATCH: error-code=10  # Request failed because the key element is not partially accessible and the provided key element length is too short or too long for that key element.
        CSM_E_KEY_EMPTY: error-code=13  # The service request failed because of uninitialized source key element.
